AUTOSAR XML (schema 00051)
package /DBC_SysDesc_Can_Network/Pkg_Cluster
  can cluster Can_Network: protocol-name=CAN
    can physical channel Can_Network_Channel: comm-connectors=Connector_Network_Can_Node0_TPMS
      frame FrameCan_BCM_01_LOGICAL_CLAMP: id 0x102, to Ecu_TPMS, frame-length=16, can-addressing-mode=STANDARD, can-fd-frame-support=false, can-frame-rx-behavior=CAN-FD  # Logical clamps, crank and starter relais (controlled by BCM) /clamp CES"
        carries pdu IPduISignal_BCM_01_LOGICAL_CLAMP: packing-byte-order=big-endian, start-position=7
        pdu IPduISignal_BCM_01_LOGICAL_CLAMP: length=16, transmission-mode-false-timing=cyclic-timing={time-offset=0.0, time-period=0.1}, transmission-mode-true-timing=cyclic-timing={time-offset=0.0, time-period=0.1}  # Logical clamps, crank and starter relais (controlled by BCM) /clamp CES
          transmission-mode-conditions:
            {data-filter={data-filter-type=NEW-IS-WITHIN, max=18446744073709551615, min=0, offset=0}, i-signal-in-i-pdu=SSecOC_MAC_BCM_01}
            {data-filter={data-filter-type=ALWAYS, max=255, min=0, offset=0}, i-signal-in-i-pdu=SSecOC_Fresh_BCM_01}
            {data-filter={data-filter-type=ALWAYS, max=3, min=0, offset=0}, i-signal-in-i-pdu=STAT_StartStopButton}
            {data-filter={data-filter-type=ALWAYS, max=3, min=0, offset=0}, i-signal-in-i-pdu=BCM_Cl30R_Off_Announcement}
            {data-filter={data-filter-type=ALWAYS, max=3, min=0, offset=0}, i-signal-in-i-pdu=BCM_Cl30s_Off_Announcement}
            {data-filter={data-filter-type=ALWAYS, max=3, min=0, offset=0}, i-signal-in-i-pdu=BCM_STAT_TransportMode}
            {data-filter={data-filter-type=ALWAYS, max=3, min=0, offset=0}, i-signal-in-i-pdu=BCM_KL15_Off_Announcement}
            {data-filter={data-filter-type=ALWAYS, max=15, min=0, offset=0}, i-signal-in-i-pdu=BCM_ST_KL}
            {data-filter={data-filter-type=ALWAYS, max=7, min=0, offset=0}, i-signal-in-i-pdu=BCM_STAT_Terminal}
            {data-filter={data-filter-type=ALWAYS, max=3, min=0, offset=0}, i-signal-in-i-pdu=BCM_STAT_CL30R_L}
            {data-filter={data-filter-type=ALWAYS, max=3, min=0, offset=0}, i-signal-in-i-pdu=BCM_STAT_CL30s_L}
            {data-filter={data-filter-type=NEW-IS-WITHIN, max=65535, min=0, offset=0}, i-signal-in-i-pdu=CRC_BCM_01}
            {data-filter={data-filter-type=ALWAYS, max=255, min=0, offset=0}, i-signal-in-i-pdu=ALIVE_BCM_01}
            {data-filter={data-filter-type=ALWAYS, max=3, min=0, offset=0}, i-signal-in-i-pdu=BCM_STAT_CL15_L}
          signal SSecOC_MAC_BCM_01: start 39, 64 bit, big-endian, init-value=0, base-type=uint64, compu {raw=phys for phys 0..1.84467440737096E19}, end-to-end-transformation-i-signal-props=data-ids=0, to Ecu_TPMS  # Short SecOC MAC signal byte 0 on CAN"
          signal SSecOC_Fresh_BCM_01: start 31, 8 bit, big-endian, init-value=0, base-type=uint8, compu {raw=phys for phys 0..255}, end-to-end-transformation-i-signal-props=data-ids=0, to Ecu_TPMS  # Short SecOC Fresh signal byte 0 on CAN"
          signal STAT_StartStopButton: start 115, 2 bit, big-endian, init-value=0, base-type=uint8, compu {phys=raw for raw 0..3, 0=NOTPRESSED, 1=PRESSED, 2=RESERVED, 3=SIGNALINVALID}, end-to-end-transformation-i-signal-props=data-ids=0, to Ecu_TPMS
          signal BCM_Cl30R_Off_Announcement: start 125, 2 bit, big-endian, init-value=0, base-type=uint8, compu {phys=raw for raw 0..3, 0=NOTAVAILABLE, 1=NO_CL30R_ANNOUNCEMENT, 2=CL30R_SHUTDOWN_ANNOUNCEMENT, 3=RESERVED}, end-to-end-transformation-i-signal-props=data-ids=0, to Ecu_TPMS
          signal BCM_Cl30s_Off_Announcement: start 127, 2 bit, big-endian, init-value=0, base-type=uint8, compu {phys=raw for raw 0..3, 0=NOTAVAILABLE, 1=NO_CL30S_ANNOUNCEMENT, 2=CL30S_SHUTDOWN_ANNOUNCEMENT, 3=RESERVED}, end-to-end-transformation-i-signal-props=data-ids=0, to Ecu_TPMS
          signal BCM_STAT_TransportMode: start 117, 2 bit, big-endian, init-value=0, base-type=uint8, compu {phys=raw for raw 0..3, 0=NOTACTIVE, 1=ACTIVE, 2=RESERVED, 3=INVALID}, end-to-end-transformation-i-signal-props=data-ids=0, to Ecu_TPMS  # Transport Mode"
          signal BCM_KL15_Off_Announcement: start 119, 2 bit, big-endian, init-value=0, base-type=uint8, compu {phys=raw for raw 0..3, 0=NOTAVAILABLE, 1=NO_ANNOUNCEMENT, 2=KL15_SHUTDOWN_ANNOUNCED, 3=RESERVED}, end-to-end-transformation-i-signal-props=data-ids=0, to Ecu_TPMS  # Before switching off the KL15 (5s), this signal gets active to inform other ECUs that the KL15 will be disabled in 5seconds if there are still no triggers to keep it active"
          signal BCM_ST_KL: start 108, 4 bit, big-endian, init-value=0, base-type=uint8, compu {phys=raw for raw 0..15, 0=INIT, 2=KL30, 15=SIGNALINVALID}, end-to-end-transformation-i-signal-props=data-ids=0, to Ecu_TPMS  # Clamp Status"
          signal BCM_STAT_Terminal: start 111, 3 bit, big-endian, init-value=0, base-type=uint8, compu {phys=raw for raw 0..7, 0=OFF, 1=THREE0S, 2=THREE0S_THREE0RON, 3=THREE0S_THREE0R_15ON, 4=RESERVED, 5=RESERVED, 6=RESERVED, 7=SIGNALINVALID}, end-to-end-transformation-i-signal-props=data-ids=0, to Ecu_TPMS  # Represent the status of physical terminal"
          signal BCM_STAT_CL30R_L: start 99, 2 bit, big-endian, init-value=3, base-type=uint8, compu {phys=raw for raw 0..3, 0=CL_30R_LOFF, 1=CL_30R_LON, 2=FAILURE, 3=SIGNALINVALID}, end-to-end-transformation-i-signal-props=data-ids=0, to Ecu_TPMS  # CL30R clamp status"
          signal BCM_STAT_CL30s_L: start 101, 2 bit, big-endian, init-value=3, base-type=uint8, compu {phys=raw for raw 0..3, 0=CL_30SOFF, 1=CL_30SON, 2=FAILURE, 3=SIGNALINVALID}, end-to-end-transformation-i-signal-props=data-ids=0, to Ecu_TPMS  # CL30s clamp status"
          signal CRC_BCM_01: start 7, 16 bit, big-endian, init-value=0, base-type=uint16, compu {raw=phys for phys 0..65535}, end-to-end-transformation-i-signal-props=data-ids=0, to Ecu_TPMS  # DataID=0x0007. Checksum calculation accordig CAN Specification. Cyclic Redundancy Check"
          signal ALIVE_BCM_01: start 23, 8 bit, big-endian, init-value=0, base-type=uint8, compu {raw=phys for phys 0..255}, end-to-end-transformation-i-signal-props=data-ids=0, to Ecu_TPMS  # Alive Counter"
          signal BCM_STAT_CL15_L: start 103, 2 bit, big-endian, init-value=3, base-type=uint8, compu {phys=raw for raw 0..3, 0=CL_15_LOFF, 1=CL_15_LON, 2=FAILURE, 3=SIGNALINVALID}, end-to-end-transformation-i-signal-props=data-ids=0, to Ecu_TPMS  # CL15 clamp status"
      frame FrameCan_CGW_01_CON_VEH: id 0x1B1, to Ecu_TPMS, frame-length=16, can-addressing-mode=STANDARD, can-fd-frame-support=false, can-frame-rx-behavior=CAN-FD  # CES clamp"
        carries pdu IPduISignal_CGW_01_CON_VEH: packing-byte-order=big-endian, start-position=7
        pdu IPduISignal_CGW_01_CON_VEH: length=16, transmission-mode-false-timing=cyclic-timing={time-offset=0.0, time-period=0.1}, transmission-mode-true-timing=cyclic-timing={time-offset=0.0, time-period=0.1}  # CES clamp
          transmission-mode-conditions:
            {data-filter={data-filter-type=NEW-IS-WITHIN, max=18446744073709551615, min=0, offset=0}, i-signal-in-i-pdu=SSecOC_MAC_CGW_01}
            {data-filter={data-filter-type=ALWAYS, max=255, min=0, offset=0}, i-signal-in-i-pdu=ALIVE_CGW_01}
            {data-filter={data-filter-type=NEW-IS-WITHIN, max=65535, min=0, offset=0}, i-signal-in-i-pdu=CRC_CGW_01}
            {data-filter={data-filter-type=ALWAYS, max=15, min=0, offset=0}, i-signal-in-i-pdu=VEH_State}
            {data-filter={data-filter-type=ALWAYS, max=255, min=0, offset=0}, i-signal-in-i-pdu=SSecOC_Fresh_CGW_01}
            {data-filter={data-filter-type=ALWAYS, max=3, min=0, offset=0}, i-signal-in-i-pdu=CGW_OBDConnectStatus}
          signal SSecOC_MAC_CGW_01: start 39, 64 bit, big-endian, init-value=0, base-type=uint64, compu {raw=phys for phys 0..1.84467440737096E19}, end-to-end-transformation-i-signal-props=data-ids=0, to Ecu_TPMS  # Short SecOC MAC signal byte 0 on CAN"
          signal ALIVE_CGW_01: start 23, 8 bit, big-endian, init-value=0, base-type=uint8, compu {raw=phys for phys 0..255}, end-to-end-transformation-i-signal-props=data-ids=0, to Ecu_TPMS  # Alive Counter"
          signal CRC_CGW_01: start 7, 16 bit, big-endian, init-value=0, base-type=uint16, compu {raw=phys for phys 0..65535}, end-to-end-transformation-i-signal-props=data-ids=0, to Ecu_TPMS  # DataID=0x0018. Checksum calculation accordig CAN Specification. Cyclic Redundancy Check"
          signal VEH_State: start 103, 4 bit, big-endian, init-value=0, base-type=uint8, compu {phys=raw for raw 0..15, 0=SLEEP, 1=ACCESS, 13=RESERVED, 2=STANDBY, 14=RESERVED, 3=PREPARE, 15=SIGNALINVALID, 4=DRIVE, 5=CHARGING, 6=DIAGNOSTIC, 7=END_DRIVE}, end-to-end-transformation-i-signal-props=data-ids=0, to Ecu_TPMS  # Vehicle Mode"
          signal SSecOC_Fresh_CGW_01: start 31, 8 bit, big-endian, init-value=0, base-type=uint8, compu {raw=phys for phys 0..255}, end-to-end-transformation-i-signal-props=data-ids=0, to Ecu_TPMS  # Short SecOC Fresh signal byte 0 on CAN"
          signal CGW_OBDConnectStatus: start 99, 2 bit, big-endian, init-value=0, base-type=uint8, compu {phys=raw for raw 0..3, 0=INITIAL, 1=CONNECTED, 2=NOTCONNECTED, 3=INVALID}, end-to-end-transformation-i-signal-props=data-ids=0, to Ecu_TPMS  # CGW send the OBD port connection status to All CANFD buses"
      frame FrameCan_Diag_ReqPhys_TPMS: id 0x18DA19F1, to Ecu_TPMS, frame-length=64, can-addressing-mode=EXTENDED, can-fd-frame-support=false, can-frame-rx-behavior=CAN-FD
        carries pdu IPduDcm_Diag_ReqPhys_TPMS: packing-byte-order=big-endian, start-position=7
        dcm i pdu IPduDcm_Diag_ReqPhys_TPMS: length=64, diag-pdu-type=DIAG-REQUEST
      frame FrameCan_ESC_01_VeloSpeed: id 0x144, to Ecu_TPMS, frame-length=48, can-addressing-mode=STANDARD, can-fd-frame-support=false, can-frame-rx-behavior=CAN-FD  # ESC_Velospeed - Vehicle speed, wheele speed, milage"
        carries pdu IPduISignal_ESC_01_VeloSpeed: packing-byte-order=big-endian, start-position=7
        pdu IPduISignal_ESC_01_VeloSpeed: length=48, transmission-mode-false-timing=cyclic-timing={time-offset=0.0, time-period=0.01}, transmission-mode-true-timing=cyclic-timing={time-offset=0.0, time-period=0.01}  # ESC_Velospeed - Vehicle speed, wheele speed, milage
          transmission-mode-conditions:
            {data-filter={data-filter-type=ALWAYS, max=15, min=0, offset=0}, i-signal-in-i-pdu=ESC_VehSpdLat_Q}
            {data-filter={data-filter-type=NEW-IS-WITHIN, max=22400, min=0, offset=0}, i-signal-in-i-pdu=ESC_VehSpdLat}
            {data-filter={data-filter-type=NEW-IS-WITHIN, max=18446744073709551615, min=0, offset=0}, i-signal-in-i-pdu=SSecOC_MAC_ESC_01}
            {data-filter={data-filter-type=ALWAYS, max=255, min=0, offset=0}, i-signal-in-i-pdu=SSecOC_Fresh_ESC_01}
            {data-filter={data-filter-type=ALWAYS, max=3, min=0, offset=0}, i-signal-in-i-pdu=ESC_WhlTck_RR_Q}
            {data-filter={data-filter-type=ALWAYS, max=3, min=0, offset=0}, i-signal-in-i-pdu=ESC_WhlTck_RL_Q}
            {data-filter={data-filter-type=ALWAYS, max=3, min=0, offset=0}, i-signal-in-i-pdu=ESC_WhlTck_FR_Q}
            {data-filter={data-filter-type=ALWAYS, max=254, min=0, offset=0}, i-signal-in-i-pdu=ESC_WhlTck_RR}
            {data-filter={data-filter-type=ALWAYS, max=254, min=0, offset=0}, i-signal-in-i-pdu=ESC_WhlTck_RL}
            {data-filter={data-filter-type=ALWAYS, max=254, min=0, offset=0}, i-signal-in-i-pdu=ESC_WhlTck_FR}
            {data-filter={data-filter-type=ALWAYS, max=3, min=0, offset=0}, i-signal-in-i-pdu=ESC_WhlTck_FL_Q}
            {data-filter={data-filter-type=ALWAYS, max=254, min=0, offset=0}, i-signal-in-i-pdu=ESC_WhlTck_FL}
            {data-filter={data-filter-type=ALWAYS, max=3, min=0, offset=0}, i-signal-in-i-pdu=ESC_WhlSpd_RR_Q}
            {data-filter={data-filter-type=NEW-IS-WITHIN, max=25600, min=-25600, offset=0}, i-signal-in-i-pdu=ESC_WhlSpd_RR}
            {data-filter={data-filter-type=ALWAYS, max=3, min=0, offset=0}, i-signal-in-i-pdu=ESC_WhlSpd_RL_Q}
            {data-filter={data-filter-type=NEW-IS-WITHIN, max=25600, min=-25600, offset=0}, i-signal-in-i-pdu=ESC_WhlSpd_RL}
            {data-filter={data-filter-type=ALWAYS, max=3, min=0, offset=0}, i-signal-in-i-pdu=ESC_WhlSpd_FR_Q}
            {data-filter={data-filter-type=NEW-IS-WITHIN, max=25600, min=-25600, offset=0}, i-signal-in-i-pdu=ESC_WhlSpd_FR}
            {data-filter={data-filter-type=ALWAYS, max=3, min=0, offset=0}, i-signal-in-i-pdu=ESC_WhlSpd_FL_Q}
            {data-filter={data-filter-type=NEW-IS-WITHIN, max=25600, min=-25600, offset=0}, i-signal-in-i-pdu=ESC_WhlSpd_FL}
            {data-filter={data-filter-type=ALWAYS, max=3, min=0, offset=0}, i-signal-in-i-pdu=ESC_VehDrvCond_Q}
            {data-filter={data-filter-type=ALWAYS, max=3, min=0, offset=0}, i-signal-in-i-pdu=ESC_DrivDist_Q}
            {data-filter={data-filter-type=ALWAYS, max=255, min=0, offset=0}, i-signal-in-i-pdu=ALIVE_ESC_01}
            {data-filter={data-filter-type=NEW-IS-WITHIN, max=65535, min=0, offset=0}, i-signal-in-i-pdu=CRC_ESC_01}
            {data-filter={data-filter-type=NEW-IS-WITHIN, max=65535, min=0, offset=0}, i-signal-in-i-pdu=ESC_DrivDist}
            {data-filter={data-filter-type=ALWAYS, max=3, min=0, offset=0}, i-signal-in-i-pdu=ESC_VehDrvCond}
            {data-filter={data-filter-type=ALWAYS, max=3, min=0, offset=0}, i-signal-in-i-pdu=ESC_VehSpd_Q}
            {data-filter={data-filter-type=NEW-IS-WITHIN, max=22400, min=0, offset=0}, i-signal-in-i-pdu=ESC_VehSpd}
          signal ESC_VehSpdLat_Q: start 311, 4 bit, big-endian, init-value=0, base-type=uint8, compu {phys=raw for raw 0..15, 11=QUALITYLIMITEDSTATUSTEMPORARY, 12=REPLACEMENTVALUESTATUSTEMP, 13=REPLACEMENTVALUE, 14=SIGNALINVALIDSTATUSTEMPORARY, 15=SIGNALINVALID, 0=INITIALIZING, 1..4=RESERVED, 5=VALID, 6..9=RESERVED, 10=VALUEISVALIDSTATUSTEMPORARY}, end-to-end-transformation-i-signal-props=data-ids=0, to Ecu_TPMS  # Qualifier Lateral Vehicle Speed"
          signal ESC_VehSpdLat: start 295, 16 bit, big-endian, init-value=0, base-type=uint16, compu {raw=phys*64 for phys 0..350; unit km_h}, end-to-end-transformation-i-signal-props=data-ids=0, to Ecu_TPMS  # Lateral Vehicle Speed (qualifier Lateral Vehicle Speed)"
          signal SSecOC_MAC_ESC_01: start 39, 64 bit, big-endian, init-value=0, base-type=uint64, compu {raw=phys for phys 0..1.84467440737096E19}, end-to-end-transformation-i-signal-props=data-ids=0, to Ecu_TPMS  # Short SecOC MAC signal byte 0 on CAN"
          signal SSecOC_Fresh_ESC_01: start 31, 8 bit, big-endian, init-value=0, base-type=uint8, compu {raw=phys for phys 0..255}, end-to-end-transformation-i-signal-props=data-ids=0, to Ecu_TPMS  # Short SecOC Fresh signal byte 0 on CAN"
          signal ESC_WhlTck_RR_Q: start 283, 2 bit, big-endian, init-value=0, base-type=uint8, compu {phys=raw for raw 0..3, 0=INITIALIZING, 1=VALID, 2=RESERVED, 3=INVALID}, end-to-end-transformation-i-signal-props=data-ids=0, to Ecu_TPMS  # Qualifier Wheel Tick RR"
          signal ESC_WhlTck_RL_Q: start 287, 2 bit, big-endian, init-value=0, base-type=uint8, compu {phys=raw for raw 0..3, 0=INITIALIZING, 1=VALID, 2=RESERVED, 3=INVALID}, end-to-end-transformation-i-signal-props=data-ids=0, to Ecu_TPMS  # Qualifier Wheel Tick RL"
          signal ESC_WhlTck_FR_Q: start 275, 2 bit, big-endian, init-value=0, base-type=uint8, compu {phys=raw for raw 0..3, 0=INITIALIZING, 1=VALID, 2=RESERVED, 3=INVALID}, end-to-end-transformation-i-signal-props=data-ids=0, to Ecu_TPMS  # Qualifier Wheel Tick FR"
          signal ESC_WhlTck_RR: start 271, 8 bit, big-endian, init-value=0, base-type=uint8, compu {raw=phys for phys 0..254; unit Tick}, end-to-end-transformation-i-signal-props=data-ids=0, to Ecu_TPMS  # Wheel tick (pulse counter) of rear right wheel. A tick is counted every rising and falling edge of teeth. The ticks are accumulated. No ticks must be lost or added."
          signal ESC_WhlTck_RL: start 263, 8 bit, big-endian, init-value=0, base-type=uint8, compu {raw=phys for phys 0..254; unit Tick}, end-to-end-transformation-i-signal-props=data-ids=0, to Ecu_TPMS  # Wheel tick (pulse counter) of rear left wheel. A tick is counted every rising and falling edge of teeth. The ticks are accumulated. No ticks must be lost or added."
          signal ESC_WhlTck_FR: start 255, 8 bit, big-endian, init-value=0, base-type=uint8, compu {raw=phys for phys 0..254; unit Tick}, end-to-end-transformation-i-signal-props=data-ids=0, to Ecu_TPMS  # Wheel tick (pulse counter) of front right wheel. A tick is counted every rising and falling edge of teeth. The ticks are accumulated. No ticks must be lost or added."
          signal ESC_WhlTck_FL_Q: start 279, 2 bit, big-endian, init-value=0, base-type=uint8, compu {phys=raw for raw 0..3, 0=INITIALIZING, 1=VALID, 2=RESERVED, 3=INVALID}, end-to-end-transformation-i-signal-props=data-ids=0, to Ecu_TPMS  # Qualifier Wheel Tick FL"
          signal ESC_WhlTck_FL: start 247, 8 bit, big-endian, init-value=0, base-type=uint8, compu {raw=phys for phys 0..254; unit Tick}, end-to-end-transformation-i-signal-props=data-ids=0, to Ecu_TPMS  # Wheel tick (pulse counter) of front left wheel. A tick is counted every rising and falling edge of teeth. The ticks are accumulated. No ticks must be lost or added."
          signal ESC_WhlSpd_RR_Q: start 223, 2 bit, big-endian, init-value=0, base-type=uint8, compu {phys=raw for raw 0..3, 0=INITIALIZING, 1=VALID, 2=REPLACEMENTVALUE, 3=SIGNALINVALID}, end-to-end-transformation-i-signal-props=data-ids=0, to Ecu_TPMS  # Qualifier wheel speed rear right"
          signal ESC_WhlSpd_RR: start 207, 16 bit, big-endian, init-value=0, base-type=sint16, compu {raw=phys*64 for phys -400..400; unit rad_s}, end-to-end-transformation-i-signal-props=data-ids=0, to Ecu_TPMS  # Measured speed of the rear right single wheel."
          signal ESC_WhlSpd_RL_Q: start 199, 2 bit, big-endian, init-value=0, base-type=uint8, compu {phys=raw for raw 0..3, 0=INITIALIZING, 1=VALID, 2=REPLACEMENTVALUE, 3=SIGNALINVALID}, end-to-end-transformation-i-signal-props=data-ids=0, to Ecu_TPMS  # Qualifier wheel speed rear left"
          signal ESC_WhlSpd_RL: start 183, 16 bit, big-endian, init-value=0, base-type=sint16, compu {raw=phys*64 for phys -400..400; unit rad_s}, end-to-end-transformation-i-signal-props=data-ids=0, to Ecu_TPMS  # Measured speed of the rear left single wheel."
          signal ESC_WhlSpd_FR_Q: start 175, 2 bit, big-endian, init-value=0, base-type=uint8, compu {phys=raw for raw 0..3, 0=INITIALIZING, 1=VALID, 2=REPLACEMENTVALUE, 3=SIGNALINVALID}, end-to-end-transformation-i-signal-props=data-ids=0, to Ecu_TPMS  # Qualifier for wheel speed front right"
          signal ESC_WhlSpd_FR: start 159, 16 bit, big-endian, init-value=0, base-type=sint16, compu {raw=phys*64 for phys -400..400; unit rad_s}, end-to-end-transformation-i-signal-props=data-ids=0, to Ecu_TPMS  # Measured speed of the front right single wheel."
          signal ESC_WhlSpd_FL_Q: start 151, 2 bit, big-endian, init-value=0, base-type=uint8, compu {phys=raw for raw 0..3, 0=INITIALIZING, 1=VALID, 2=REPLACEMENTVALUE, 3=SIGNALINVALID}, end-to-end-transformation-i-signal-props=data-ids=0, to Ecu_TPMS  # Qualifier for wheel speed front left"
          signal ESC_WhlSpd_FL: start 135, 16 bit, big-endian, init-value=0, base-type=sint16, compu {raw=phys*64 for phys -400..400; unit rad_s}, end-to-end-transformation-i-signal-props=data-ids=0, to Ecu_TPMS  # Measured speed of the front left single wheel."
          signal ESC_VehDrvCond_Q: start 127, 2 bit, big-endian, init-value=0, base-type=uint8, compu {phys=raw for raw 0..3, 0=INITIALIZING, 1=VALID, 2=RESERVED, 3=SIGNALINVALID}, end-to-end-transformation-i-signal-props=data-ids=0, to Ecu_TPMS  # Qualifier Driving Condition Detected: Stationary, Moving Forwards, Moving Backwards"
          signal ESC_DrivDist_Q: start 219, 2 bit, big-endian, init-value=0, base-type=uint8, compu {phys=raw for raw 0..3, 0=INITIALIZING, 1=VALID, 2=RESERVED, 3=INVALID}, end-to-end-transformation-i-signal-props=data-ids=0, to Ecu_TPMS  # Qualifier ESC_Mileage: 1 cm / Digit; invalid value FFFFh, input for Mileage calc, in cm, reset each clamp change"
          signal ALIVE_ESC_01: start 23, 8 bit, big-endian, init-value=0, base-type=uint8, compu {raw=phys for phys 0..255}, end-to-end-transformation-i-signal-props=data-ids=0, to Ecu_TPMS  # Alive Counter"
          signal CRC_ESC_01: start 7, 16 bit, big-endian, init-value=0, base-type=uint16, compu {raw=phys for phys 0..65535}, end-to-end-transformation-i-signal-props=data-ids=0, to Ecu_TPMS  # DataID=0x0025. Checksum calculation accordig CAN Specification. Cyclic Redundancy Check"
          signal ESC_DrivDist: start 231, 16 bit, big-endian, init-value=0, base-type=uint16, compu {raw=phys for phys 0..65535; unit cm}, end-to-end-transformation-i-signal-props=data-ids=0, to Ecu_TPMS  # ESC_Mileage: 1 cm / Digit; invalid value FFFFh, input for Mileage calc, in cm, reset each clamp change"
          signal ESC_VehDrvCond: start 115, 2 bit, big-endian, init-value=0, base-type=uint8, compu {phys=raw for raw 0..3, 0=STANDSTILL, 1=FORWARD, 2=BACKWARD, 3=INVALID}, end-to-end-transformation-i-signal-props=data-ids=0, to Ecu_TPMS  # Driving Condition Detected: Driving condition Values 4,5,6 describe if the axle are on the chassis dynamometer roller dynamometer test bench; Value 3 described when the recognition of the moving direction isn't recognised."
          signal ESC_VehSpd_Q: start 119, 2 bit, big-endian, init-value=0, base-type=uint8, compu {phys=raw for raw 0..3, 0=INITIALIZING, 1=VALID, 2=QUALITYLIMITEDSTATUSTEMP, 3=SIGNALINVALID}, end-to-end-transformation-i-signal-props=data-ids=0, to Ecu_TPMS  # Qualifier Vehicle Speed"
          signal ESC_VehSpd: start 103, 16 bit, big-endian, init-value=0, base-type=uint16, compu {raw=phys*64 for phys 0..350; unit km_h}, end-to-end-transformation-i-signal-props=data-ids=0, to Ecu_TPMS  # Vehicle Speed"
      frame FrameCan_ESC_05_OTA: id 0x312, to Ecu_TPMS, frame-length=16, can-addressing-mode=STANDARD, can-fd-frame-support=false, can-frame-rx-behavior=CAN-FD
        carries pdu IPduISignal_ESC_05_OTA: packing-byte-order=big-endian, start-position=7
        pdu IPduISignal_ESC_05_OTA: length=16, transmission-mode-false-timing=cyclic-timing={time-offset=0.0, time-period=0.5}, transmission-mode-true-timing=cyclic-timing={time-offset=0.0, time-period=0.5}
          transmission-mode-conditions:
            {data-filter={data-filter-type=ALWAYS, max=255, min=0, offset=0}, i-signal-in-i-pdu=ALIVE_ESC_05}
            {data-filter={data-filter-type=NEW-IS-WITHIN, max=65535, min=0, offset=0}, i-signal-in-i-pdu=CRC_ESC_05}
            {data-filter={data-filter-type=ALWAYS, max=3, min=0, offset=0}, i-signal-in-i-pdu=ESC_OTA_inhib_FB}
          signal ALIVE_ESC_05: start 23, 8 bit, big-endian, init-value=0, base-type=uint8, compu {raw=phys for phys 0..255}, end-to-end-transformation-i-signal-props=data-ids=0, to Ecu_TPMS  # Alive Counter"
          signal CRC_ESC_05: start 7, 16 bit, big-endian, init-value=0, base-type=uint16, compu {raw=phys for phys 0..65535}, end-to-end-transformation-i-signal-props=data-ids=0, to Ecu_TPMS  # DataID=0x0029. Checksum calculation accordig CAN Specification. Cyclic Redundancy Check"
          signal ESC_OTA_inhib_FB: start 103, 2 bit, big-endian, init-value=0, base-type=uint8, compu {phys=raw for raw 0..3, 0=INITIAL, 1=INHIBITED, 2=NOTINHIBITED, 3=INVALID}, end-to-end-transformation-i-signal-props=data-ids=0, to Ecu_TPMS  # ESC execute the inhibition and send the Feedback to all CANFD ECUs"
      frame FrameCan_HU_01_OTA: id 0x313, to Ecu_TPMS, frame-length=16, can-addressing-mode=STANDARD, can-fd-frame-support=false, can-frame-rx-behavior=CAN-FD
        carries pdu IPduISignal_HU_01_OTA: packing-byte-order=big-endian, start-position=7
        pdu IPduISignal_HU_01_OTA: length=16, transmission-mode-false-timing=cyclic-timing={time-offset=0.0, time-period=0.5}, transmission-mode-true-timing=cyclic-timing={time-offset=0.0, time-period=0.5}
          transmission-mode-conditions:
            {data-filter={data-filter-type=ALWAYS, max=255, min=0, offset=0}, i-signal-in-i-pdu=ALIVE_HU_01}
            {data-filter={data-filter-type=NEW-IS-WITHIN, max=65535, min=0, offset=0}, i-signal-in-i-pdu=CRC_HU_01}
            {data-filter={data-filter-type=ALWAYS, max=7, min=0, offset=0}, i-signal-in-i-pdu=HU_OTA_UpdateConfirm}
          signal ALIVE_HU_01: start 23, 8 bit, big-endian, init-value=0, base-type=uint8, compu {raw=phys for phys 0..255}, end-to-end-transformation-i-signal-props=data-ids=0, to Ecu_TPMS  # Alive Counter"
          signal CRC_HU_01: start 7, 16 bit, big-endian, init-value=0, base-type=uint16, compu {raw=phys for phys 0..65535}, end-to-end-transformation-i-signal-props=data-ids=0, to Ecu_TPMS  # DataID=0x002D. Checksum calculation accordig CAN Specification. Cyclic Redundancy Check"
          signal HU_OTA_UpdateConfirm: start 103, 3 bit, big-endian, init-value=0, base-type=uint8, compu {phys=raw for raw 0..7, 0=INITIAL, 1=OTAUPDATECONFIRMED, 2=OTAFINISHED, 3..6=RESERVED, 7=INVALID}, end-to-end-transformation-i-signal-props=data-ids=0, to Ecu_TPMS  # HU send the input confirmation of updating from user to all CANFD ECUs"
      frame FrameCan_HU_03_SET_FUNC: id 0x3FA, to Ecu_TPMS, frame-length=16, can-addressing-mode=STANDARD, can-fd-frame-support=false, can-frame-rx-behavior=CAN-FD  # Settings for customer functions, mode functions"
        carries pdu IPduISignal_HU_03_SET_FUNC: packing-byte-order=big-endian, start-position=7
        pdu IPduISignal_HU_03_SET_FUNC: length=16  # Settings for customer functions, mode functions
          transmission-mode-conditions:
            {data-filter={data-filter-type=ALWAYS, max=0, min=0, offset=0}, i-signal-in-i-pdu=SET_TowMode}
            {data-filter={data-filter-type=ALWAYS, max=255, min=0, offset=0}, i-signal-in-i-pdu=ALIVE_HU_03}
            {data-filter={data-filter-type=NEW-IS-WITHIN, max=65535, min=0, offset=0}, i-signal-in-i-pdu=CRC_HU_03}
            {data-filter={data-filter-type=ALWAYS, max=3, min=0, offset=0}, i-signal-in-i-pdu=SteeringHeatingRequest}
            {data-filter={data-filter-type=ALWAYS, max=3, min=0, offset=0}, i-signal-in-i-pdu=SET_InteriorMotionSensing}
            {data-filter={data-filter-type=ALWAYS, max=3, min=0, offset=0}, i-signal-in-i-pdu=SET_RCP_Button}
            {data-filter={data-filter-type=ALWAYS, max=100, min=0, offset=0}, i-signal-in-i-pdu=DimmingVehicleBrightness}
            {data-filter={data-filter-type=ALWAYS, max=3, min=0, offset=0}, i-signal-in-i-pdu=SET_DayTimeRunningLight}
            {data-filter={data-filter-type=ALWAYS, max=7, min=0, offset=0}, i-signal-in-i-pdu=SET_LeavingHomeSetting}
            {data-filter={data-filter-type=ALWAYS, max=7, min=0, offset=0}, i-signal-in-i-pdu=SET_ComingHomeSetting}
            {data-filter={data-filter-type=ALWAYS, max=3, min=0, offset=0}, i-signal-in-i-pdu=SET_ToDefaultFactorySetting}
            {data-filter={data-filter-type=ALWAYS, max=3, min=0, offset=0}, i-signal-in-i-pdu=SET_RemoteLockFeedback}
          signal SET_TowMode: start 127, 2 bit, big-endian, init-value=0, base-type=uint8, compu {phys=raw for raw 0, 0=OFF, 1=ON, 2=NOCHANGE, 3=SIGNALINVALID}, end-to-end-transformation-i-signal-props=data-ids=0, to Ecu_TPMS
          signal ALIVE_HU_03: start 23, 8 bit, big-endian, init-value=0, base-type=uint8, compu {raw=phys for phys 0..255}, end-to-end-transformation-i-signal-props=data-ids=0, to Ecu_TPMS  # Alive Counter"
          signal CRC_HU_03: start 7, 16 bit, big-endian, init-value=0, base-type=uint16, compu {raw=phys for phys 0..65535}, end-to-end-transformation-i-signal-props=data-ids=0, to Ecu_TPMS  # DataID=0x002F. Checksum calculation accordig CAN Specification. Cyclic Redundancy Check"
          signal SteeringHeatingRequest: start 117, 2 bit, big-endian, init-value=0, base-type=uint8, compu {raw=phys for phys 0..3}, end-to-end-transformation-i-signal-props=data-ids=0, to Ecu_TPMS
          signal SET_InteriorMotionSensing: start 119, 2 bit, big-endian, init-value=0, base-type=uint8, compu {phys=raw for raw 0..3, 0=OFF, 1=ON, 2=NOCHANGE, 3=SIGNALINVALID}, end-to-end-transformation-i-signal-props=data-ids=0, to Ecu_TPMS
          signal SET_RCP_Button: start 113, 2 bit, big-endian, init-value=0, base-type=uint8, compu {phys=raw for raw 0..3, 0=NOTPRESSED, 1=PRESSED, 2=RESERVED, 3=SIGNALINVALID}, end-to-end-transformation-i-signal-props=data-ids=0, to Ecu_TPMS  # RCP softbutton status inside ICH, Display menue button information"
          signal DimmingVehicleBrightness: start 111, 8 bit, big-endian, init-value=0, base-type=uint8, compu {raw=phys for phys 0..100; unit pct}, end-to-end-transformation-i-signal-props=data-ids=0, to Ecu_TPMS  # 255 invalid value. Valid range 0 - 100% Values between 101 and 254 are reserved. Used for PWM control of clamp 58,"
          signal SET_DayTimeRunningLight: start 103, 2 bit, big-endian, init-value=0, base-type=uint8, compu {phys=raw for raw 0..3, 0=OFF, 1=ON, 2=RESERVED, 3=SIGNALINVALID}, end-to-end-transformation-i-signal-props=data-ids=0, to Ecu_TPMS  # Activation of the day time running light"
          signal SET_LeavingHomeSetting: start 98, 3 bit, big-endian, init-value=0, base-type=uint8, compu {phys=raw for raw 0..7, 0=OFF, 1=TWO0, 2=FOUR0, 3=SIX0, 4=EIGHT0, 5=RESERVED, 6=NOCHANGE, 7=SIGNALINVALID; unit Bit}, end-to-end-transformation-i-signal-props=data-ids=0, to Ecu_TPMS  # Setting for follow me home light function Invalid value = 3"
          signal SET_ComingHomeSetting: start 101, 3 bit, big-endian, init-value=0, base-type=uint8, compu {phys=raw for raw 0..7, 0=OFF, 1=TWO0, 2=FOUR0, 3=SIX0, 4=EIGHT0, 5=RESERVED, 6=NOCHANGE, 7=SIGNALINVALID; unit Bit}, end-to-end-transformation-i-signal-props=data-ids=0, to Ecu_TPMS  # Setting for Leaving home light"
          signal SET_ToDefaultFactorySetting: start 115, 2 bit, big-endian, init-value=0, base-type=uint8, compu {phys=raw for raw 0..3, 0=OFF, 1=ON, 2=RESERVED, 3=SIGNALINVALID_NOCHANGE}, end-to-end-transformation-i-signal-props=data-ids=0, to Ecu_TPMS  # Settings to default values for the ECU's,"
          signal SET_RemoteLockFeedback: start 125, 2 bit, big-endian, init-value=0, base-type=uint8, compu {phys=raw for raw 0..3, 0=NOFEEDBACK, 1=TURNINDICATOR, 2=TURNINDICATOR_TOOT, 3=SIGNALINVALID}, end-to-end-transformation-i-signal-props=data-ids=0, to Ecu_TPMS  # Remote Lock feedback: customer can choose light feedback when lock the door with remote key"
      frame FrameCan_NM_EPS: id 0x510, to Ecu_TPMS, frame-length=8, can-addressing-mode=STANDARD  # Networkmanagement message"
        carries pdu IPduISignal_NM_EPS: packing-byte-order=big-endian, start-position=7
        pdu IPduISignal_NM_EPS: length=8  # Networkmanagement message
          transmission-mode-conditions:
            {data-filter={data-filter-type=ALWAYS, max=1, min=0, offset=0}, i-signal-in-i-pdu=usrData1_EPS_Bit7_ECUSPEC_AWAKE}
            {data-filter={data-filter-type=ALWAYS, max=1, min=0, offset=0}, i-signal-in-i-pdu=usrData1_EPS_Bit6_DIAGN_AWAKE}
            {data-filter={data-filter-type=ALWAYS, max=1, min=0, offset=0}, i-signal-in-i-pdu=usrData1_EPS_Bit5_IGNITION_AWAKE}
            {data-filter={data-filter-type=ALWAYS, max=1, min=0, offset=0}, i-signal-in-i-pdu=usrData1_EPS_Bit4_NETWORK_AWAKE}
            {data-filter={data-filter-type=ALWAYS, max=1, min=0, offset=0}, i-signal-in-i-pdu=usrData1_EPS_Bit3_ECUSPEC_WAKEUP}
            {data-filter={data-filter-type=ALWAYS, max=1, min=0, offset=0}, i-signal-in-i-pdu=usrData1_EPS_Bit2_NETWORK_WAKEUP}
            {data-filter={data-filter-type=ALWAYS, max=1, min=0, offset=0}, i-signal-in-i-pdu=usrData1_EPS_Bit1_RESET_WAKEUP}
            {data-filter={data-filter-type=ALWAYS, max=1, min=0, offset=0}, i-signal-in-i-pdu=CtrlBitVector_EPS_Bit7_Res}
            {data-filter={data-filter-type=ALWAYS, max=1, min=0, offset=0}, i-signal-in-i-pdu=CtrlBitVector_EPS_Bit6_PNI}
            {data-filter={data-filter-type=ALWAYS, max=1, min=0, offset=0}, i-signal-in-i-pdu=CtrlBitVector_EPS_Bit5_Res}
            {data-filter={data-filter-type=ALWAYS, max=1, min=0, offset=0}, i-signal-in-i-pdu=CtrlBitVector_EPS_Bit4_ActWake}
            {data-filter={data-filter-type=ALWAYS, max=1, min=0, offset=0}, i-signal-in-i-pdu=CtrlBitVector_EPS_Bit3_NMCoord}
            {data-filter={data-filter-type=ALWAYS, max=1, min=0, offset=0}, i-signal-in-i-pdu=CtrlBitVector_EPS_Bit2_Res}
            {data-filter={data-filter-type=ALWAYS, max=1, min=0, offset=0}, i-signal-in-i-pdu=CtrlBitVector_EPS_Bit1_Res}
            {data-filter={data-filter-type=ALWAYS, max=1, min=0, offset=0}, i-signal-in-i-pdu=usrData1_EPS_Bit0_IGN_WAKEUP}
            {data-filter={data-filter-type=ALWAYS, max=255, min=0, offset=0}, i-signal-in-i-pdu=usrData0_EPS}
            {data-filter={data-filter-type=ALWAYS, max=127, min=0, offset=0}, i-signal-in-i-pdu=srcNodeID_EPS}
            {data-filter={data-filter-type=ALWAYS, max=1, min=0, offset=0}, i-signal-in-i-pdu=CtrlBitVector_EPS_Bit0_RMR}
            {data-filter={data-filter-type=ALWAYS, max=255, min=0, offset=0}, i-signal-in-i-pdu=usrData2_EPS}
            {data-filter={data-filter-type=ALWAYS, max=255, min=0, offset=0}, i-signal-in-i-pdu=usrData4_EPS_PN_Info1}
            {data-filter={data-filter-type=ALWAYS, max=255, min=0, offset=0}, i-signal-in-i-pdu=usrData5_EPS_PN_Info2}
            {data-filter={data-filter-type=ALWAYS, max=255, min=0, offset=0}, i-signal-in-i-pdu=usrData3_EPS}
          signal usrData1_EPS_Bit7_ECUSPEC_AWAKE: start 31, 1 bit, big-endian, init-value=0, base-type=uint8, compu {phys=raw for raw 0..1, 0=INACTIVE, 1=ACTIVE}, end-to-end-transformation-i-signal-props=data-ids=0, to Ecu_TPMS
          signal usrData1_EPS_Bit6_DIAGN_AWAKE: start 30, 1 bit, big-endian, init-value=0, base-type=uint8, compu {phys=raw for raw 0..1, 0=INACTIVE, 1=ACTIVE}, end-to-end-transformation-i-signal-props=data-ids=0, to Ecu_TPMS
          signal usrData1_EPS_Bit5_IGNITION_AWAKE: start 29, 1 bit, big-endian, init-value=0, base-type=uint8, compu {phys=raw for raw 0..1, 0=INACTIVE, 1=ACTIVE}, end-to-end-transformation-i-signal-props=data-ids=0, to Ecu_TPMS
          signal usrData1_EPS_Bit4_NETWORK_AWAKE: start 28, 1 bit, big-endian, init-value=0, base-type=uint8, compu {phys=raw for raw 0..1, 0=INACTIVE, 1=ACTIVE}, end-to-end-transformation-i-signal-props=data-ids=0, to Ecu_TPMS
          signal usrData1_EPS_Bit3_ECUSPEC_WAKEUP: start 27, 1 bit, big-endian, init-value=0, base-type=uint8, compu {phys=raw for raw 0..1, 0=INACTIVE, 1=ACTIVE}, end-to-end-transformation-i-signal-props=data-ids=0, to Ecu_TPMS
          signal usrData1_EPS_Bit2_NETWORK_WAKEUP: start 26, 1 bit, big-endian, init-value=0, base-type=uint8, compu {phys=raw for raw 0..1, 0=INACTIVE, 1=ACTIVE}, end-to-end-transformation-i-signal-props=data-ids=0, to Ecu_TPMS
          signal usrData1_EPS_Bit1_RESET_WAKEUP: start 25, 1 bit, big-endian, init-value=0, base-type=uint8, compu {phys=raw for raw 0..1, 0=INACTIVE, 1=ACTIVE}, end-to-end-transformation-i-signal-props=data-ids=0, to Ecu_TPMS
          signal CtrlBitVector_EPS_Bit7_Res: start 15, 1 bit, big-endian, init-value=0, base-type=uint8, compu {raw=phys for phys 0..1}, end-to-end-transformation-i-signal-props=data-ids=0, to Ecu_TPMS
          signal CtrlBitVector_EPS_Bit6_PNI: start 14, 1 bit, big-endian, init-value=0, base-type=uint8, compu {raw=phys for phys 0..1}, end-to-end-transformation-i-signal-props=data-ids=0, to Ecu_TPMS
          signal CtrlBitVector_EPS_Bit5_Res: start 13, 1 bit, big-endian, init-value=0, base-type=uint8, compu {raw=phys for phys 0..1}, end-to-end-transformation-i-signal-props=data-ids=0, to Ecu_TPMS
          signal CtrlBitVector_EPS_Bit4_ActWake: start 12, 1 bit, big-endian, init-value=0, base-type=uint8, compu {raw=phys for phys 0..1}, end-to-end-transformation-i-signal-props=data-ids=0, to Ecu_TPMS
          signal CtrlBitVector_EPS_Bit3_NMCoord: start 11, 1 bit, big-endian, init-value=0, base-type=uint8, compu {phys=raw for raw 0..1, 0=STARTOFSYNCHRONIZEDSHUTDOWNISNOTREQUESTEDBYMAINCOORDINATOR, 1=STARTOFSYNCHRONIZEDSHUTDOWNISREQUESTEDBYMAINCOORDINATOR}, end-to-end-transformation-i-signal-props=data-ids=0, to Ecu_TPMS
          signal CtrlBitVector_EPS_Bit2_Res: start 10, 1 bit, big-endian, init-value=0, base-type=uint8, compu {raw=phys for phys 0..1}, end-to-end-transformation-i-signal-props=data-ids=0, to Ecu_TPMS
          signal CtrlBitVector_EPS_Bit1_Res: start 9, 1 bit, big-endian, init-value=0, base-type=uint8, compu {raw=phys for phys 0..1}, end-to-end-transformation-i-signal-props=data-ids=0, to Ecu_TPMS
          signal usrData1_EPS_Bit0_IGN_WAKEUP: start 24, 1 bit, big-endian, init-value=0, base-type=uint8, compu {phys=raw for raw 0..1, 0=INACTIVE, 1=ACTIVE}, end-to-end-transformation-i-signal-props=data-ids=0, to Ecu_TPMS
          signal usrData0_EPS: start 23, 8 bit, big-endian, init-value=0, base-type=uint8, compu {phys=raw for raw 0..255, 0=USERDATAFORCURRENTVEHICLEWITHOUTPARTIALNETWORKING, 1=USERDATAFORCURRENTVEHICLEWITHPARTIALNETWORKING, 255=USERDATANOTUSED}, end-to-end-transformation-i-signal-props=data-ids=0, to Ecu_TPMS
          signal srcNodeID_EPS: start 7, 8 bit, big-endian, init-value=0, base-type=uint8, compu {raw=phys for phys 0..127}, end-to-end-transformation-i-signal-props=data-ids=0, to Ecu_TPMS
          signal CtrlBitVector_EPS_Bit0_RMR: start 8, 1 bit, big-endian, init-value=0, base-type=uint8, compu {raw=phys for phys 0..1}, end-to-end-transformation-i-signal-props=data-ids=0, to Ecu_TPMS
          signal usrData2_EPS: start 39, 8 bit, big-endian, init-value=0, base-type=uint8, compu {raw=phys for phys 0..255}, end-to-end-transformation-i-signal-props=data-ids=0, to Ecu_TPMS
          signal usrData4_EPS_PN_Info1: start 55, 8 bit, big-endian, init-value=0, base-type=uint8, compu {raw=phys for phys 0..255}, end-to-end-transformation-i-signal-props=data-ids=0, to Ecu_TPMS
          signal usrData5_EPS_PN_Info2: start 63, 8 bit, big-endian, init-value=0, base-type=uint8, compu {raw=phys for phys 0..255}, end-to-end-transformation-i-signal-props=data-ids=0, to Ecu_TPMS
          signal usrData3_EPS: start 47, 8 bit, big-endian, init-value=0, base-type=uint8, compu {raw=phys for phys 0..255}, end-to-end-transformation-i-signal-props=data-ids=0, to Ecu_TPMS
      frame FrameCan_NM_ESC: id 0x50F, to Ecu_TPMS, frame-length=8, can-addressing-mode=STANDARD  # Networkmanagement message"
        carries pdu IPduISignal_NM_ESC: packing-byte-order=big-endian, start-position=7
        pdu IPduISignal_NM_ESC: length=8  # Networkmanagement message
          transmission-mode-conditions:
            {data-filter={data-filter-type=ALWAYS, max=1, min=0, offset=0}, i-signal-in-i-pdu=usrData1_ESC_Bit7_ECUSPEC_AWAKE}
            {data-filter={data-filter-type=ALWAYS, max=1, min=0, offset=0}, i-signal-in-i-pdu=usrData1_ESC_Bit6_DIAGN_AWAKE}
            {data-filter={data-filter-type=ALWAYS, max=1, min=0, offset=0}, i-signal-in-i-pdu=usrData1_ESC_Bit5_IGNITION_AWAKE}
            {data-filter={data-filter-type=ALWAYS, max=1, min=0, offset=0}, i-signal-in-i-pdu=usrData1_ESC_Bit4_NETWORK_AWAKE}
            {data-filter={data-filter-type=ALWAYS, max=1, min=0, offset=0}, i-signal-in-i-pdu=usrData1_ESC_Bit3_ECUSPEC_WAKEUP}
            {data-filter={data-filter-type=ALWAYS, max=1, min=0, offset=0}, i-signal-in-i-pdu=usrData1_ESC_Bit2_NETWORK_WAKEUP}
            {data-filter={data-filter-type=ALWAYS, max=1, min=0, offset=0}, i-signal-in-i-pdu=usrData1_ESC_Bit1_RESET_WAKEUP}
            {data-filter={data-filter-type=ALWAYS, max=1, min=0, offset=0}, i-signal-in-i-pdu=CtrlBitVector_ESC_Bit7_Res}
            {data-filter={data-filter-type=ALWAYS, max=1, min=0, offset=0}, i-signal-in-i-pdu=CtrlBitVector_ESC_Bit6_PNI}
            {data-filter={data-filter-type=ALWAYS, max=1, min=0, offset=0}, i-signal-in-i-pdu=CtrlBitVector_ESC_Bit5_Res}
            {data-filter={data-filter-type=ALWAYS, max=1, min=0, offset=0}, i-signal-in-i-pdu=CtrlBitVector_ESC_Bit4_ActWake}
            {data-filter={data-filter-type=ALWAYS, max=1, min=0, offset=0}, i-signal-in-i-pdu=CtrlBitVector_ESC_Bit3_NMCoord}
            {data-filter={data-filter-type=ALWAYS, max=1, min=0, offset=0}, i-signal-in-i-pdu=CtrlBitVector_ESC_Bit2_Res}
            {data-filter={data-filter-type=ALWAYS, max=1, min=0, offset=0}, i-signal-in-i-pdu=CtrlBitVector_ESC_Bit1_Res}
            {data-filter={data-filter-type=ALWAYS, max=1, min=0, offset=0}, i-signal-in-i-pdu=usrData1_ESC_Bit0_IGN_WAKEUP}
            {data-filter={data-filter-type=ALWAYS, max=255, min=0, offset=0}, i-signal-in-i-pdu=usrData0_ESC}
            {data-filter={data-filter-type=ALWAYS, max=127, min=0, offset=0}, i-signal-in-i-pdu=srcNodeID_ESC}
            {data-filter={data-filter-type=ALWAYS, max=1, min=0, offset=0}, i-signal-in-i-pdu=CtrlBitVector_ESC_Bit0_RMR}
            {data-filter={data-filter-type=ALWAYS, max=255, min=0, offset=0}, i-signal-in-i-pdu=usrData2_ESC}
            {data-filter={data-filter-type=ALWAYS, max=255, min=0, offset=0}, i-signal-in-i-pdu=usrData4_ESC_PN_Info1}
            {data-filter={data-filter-type=ALWAYS, max=255, min=0, offset=0}, i-signal-in-i-pdu=usrData5_ESC_PN_Info2}
            {data-filter={data-filter-type=ALWAYS, max=255, min=0, offset=0}, i-signal-in-i-pdu=usrData3_ESC}
          signal usrData1_ESC_Bit7_ECUSPEC_AWAKE: start 31, 1 bit, big-endian, init-value=0, base-type=uint8, compu {phys=raw for raw 0..1, 0=INACTIVE, 1=ACTIVE}, end-to-end-transformation-i-signal-props=data-ids=0, to Ecu_TPMS
          signal usrData1_ESC_Bit6_DIAGN_AWAKE: start 30, 1 bit, big-endian, init-value=0, base-type=uint8, compu {phys=raw for raw 0..1, 0=INACTIVE, 1=ACTIVE}, end-to-end-transformation-i-signal-props=data-ids=0, to Ecu_TPMS
          signal usrData1_ESC_Bit5_IGNITION_AWAKE: start 29, 1 bit, big-endian, init-value=0, base-type=uint8, compu {phys=raw for raw 0..1, 0=INACTIVE, 1=ACTIVE}, end-to-end-transformation-i-signal-props=data-ids=0, to Ecu_TPMS
          signal usrData1_ESC_Bit4_NETWORK_AWAKE: start 28, 1 bit, big-endian, init-value=0, base-type=uint8, compu {phys=raw for raw 0..1, 0=INACTIVE, 1=ACTIVE}, end-to-end-transformation-i-signal-props=data-ids=0, to Ecu_TPMS
          signal usrData1_ESC_Bit3_ECUSPEC_WAKEUP: start 27, 1 bit, big-endian, init-value=0, base-type=uint8, compu {phys=raw for raw 0..1, 0=INACTIVE, 1=ACTIVE}, end-to-end-transformation-i-signal-props=data-ids=0, to Ecu_TPMS
          signal usrData1_ESC_Bit2_NETWORK_WAKEUP: start 26, 1 bit, big-endian, init-value=0, base-type=uint8, compu {phys=raw for raw 0..1, 0=INACTIVE, 1=ACTIVE}, end-to-end-transformation-i-signal-props=data-ids=0, to Ecu_TPMS
          signal usrData1_ESC_Bit1_RESET_WAKEUP: start 25, 1 bit, big-endian, init-value=0, base-type=uint8, compu {phys=raw for raw 0..1, 0=INACTIVE, 1=ACTIVE}, end-to-end-transformation-i-signal-props=data-ids=0, to Ecu_TPMS
          signal CtrlBitVector_ESC_Bit7_Res: start 15, 1 bit, big-endian, init-value=0, base-type=uint8, compu {raw=phys for phys 0..1}, end-to-end-transformation-i-signal-props=data-ids=0, to Ecu_TPMS
          signal CtrlBitVector_ESC_Bit6_PNI: start 14, 1 bit, big-endian, init-value=0, base-type=uint8, compu {raw=phys for phys 0..1}, end-to-end-transformation-i-signal-props=data-ids=0, to Ecu_TPMS
          signal CtrlBitVector_ESC_Bit5_Res: start 13, 1 bit, big-endian, init-value=0, base-type=uint8, compu {raw=phys for phys 0..1}, end-to-end-transformation-i-signal-props=data-ids=0, to Ecu_TPMS
          signal CtrlBitVector_ESC_Bit4_ActWake: start 12, 1 bit, big-endian, init-value=0, base-type=uint8, compu {raw=phys for phys 0..1}, end-to-end-transformation-i-signal-props=data-ids=0, to Ecu_TPMS
          signal CtrlBitVector_ESC_Bit3_NMCoord: start 11, 1 bit, big-endian, init-value=0, base-type=uint8, compu {phys=raw for raw 0..1, 0=STARTOFSYNCHRONIZEDSHUTDOWNISNOTREQUESTEDBYMAINCOORDINATOR, 1=STARTOFSYNCHRONIZEDSHUTDOWNISREQUESTEDBYMAINCOORDINATOR}, end-to-end-transformation-i-signal-props=data-ids=0, to Ecu_TPMS
          signal CtrlBitVector_ESC_Bit2_Res: start 10, 1 bit, big-endian, init-value=0, base-type=uint8, compu {raw=phys for phys 0..1}, end-to-end-transformation-i-signal-props=data-ids=0, to Ecu_TPMS
          signal CtrlBitVector_ESC_Bit1_Res: start 9, 1 bit, big-endian, init-value=0, base-type=uint8, compu {raw=phys for phys 0..1}, end-to-end-transformation-i-signal-props=data-ids=0, to Ecu_TPMS
          signal usrData1_ESC_Bit0_IGN_WAKEUP: start 24, 1 bit, big-endian, init-value=0, base-type=uint8, compu {phys=raw for raw 0..1, 0=INACTIVE, 1=ACTIVE}, end-to-end-transformation-i-signal-props=data-ids=0, to Ecu_TPMS
          signal usrData0_ESC: start 23, 8 bit, big-endian, init-value=0, base-type=uint8, compu {phys=raw for raw 0..255, 0=USERDATAFORCURRENTVEHICLEWITHOUTPARTIALNETWORKING, 1=USERDATAFORCURRENTVEHICLEWITHPARTIALNETWORKING, 255=USERDATANOTUSED}, end-to-end-transformation-i-signal-props=data-ids=0, to Ecu_TPMS
          signal srcNodeID_ESC: start 7, 8 bit, big-endian, init-value=0, base-type=uint8, compu {raw=phys for phys 0..127}, end-to-end-transformation-i-signal-props=data-ids=0, to Ecu_TPMS
          signal CtrlBitVector_ESC_Bit0_RMR: start 8, 1 bit, big-endian, init-value=0, base-type=uint8, compu {raw=phys for phys 0..1}, end-to-end-transformation-i-signal-props=data-ids=0, to Ecu_TPMS
          signal usrData2_ESC: start 39, 8 bit, big-endian, init-value=0, base-type=uint8, compu {raw=phys for phys 0..255}, end-to-end-transformation-i-signal-props=data-ids=0, to Ecu_TPMS
          signal usrData4_ESC_PN_Info1: start 55, 8 bit, big-endian, init-value=0, base-type=uint8, compu {raw=phys for phys 0..255}, end-to-end-transformation-i-signal-props=data-ids=0, to Ecu_TPMS
          signal usrData5_ESC_PN_Info2: start 63, 8 bit, big-endian, init-value=0, base-type=uint8, compu {raw=phys for phys 0..255}, end-to-end-transformation-i-signal-props=data-ids=0, to Ecu_TPMS
          signal usrData3_ESC: start 47, 8 bit, big-endian, init-value=0, base-type=uint8, compu {raw=phys for phys 0..255}, end-to-end-transformation-i-signal-props=data-ids=0, to Ecu_TPMS
      frame FrameCan_NM_FCM: id 0x505, to Ecu_TPMS, frame-length=8, can-addressing-mode=STANDARD  # Networkmanagement message"
        carries pdu IPduISignal_NM_FCM: packing-byte-order=big-endian, start-position=7
        pdu IPduISignal_NM_FCM: length=8  # Networkmanagement message
          transmission-mode-conditions:
            {data-filter={data-filter-type=ALWAYS, max=1, min=0, offset=0}, i-signal-in-i-pdu=usrData1_FCM_Bit7_ECUSPEC_AWAKE}
            {data-filter={data-filter-type=ALWAYS, max=1, min=0, offset=0}, i-signal-in-i-pdu=usrData1_FCM_Bit6_DIAGN_AWAKE}
            {data-filter={data-filter-type=ALWAYS, max=1, min=0, offset=0}, i-signal-in-i-pdu=usrData1_FCM_Bit5_IGNITION_AWAKE}
            {data-filter={data-filter-type=ALWAYS, max=1, min=0, offset=0}, i-signal-in-i-pdu=usrData1_FCM_Bit4_NETWORK_AWAKE}
            {data-filter={data-filter-type=ALWAYS, max=1, min=0, offset=0}, i-signal-in-i-pdu=usrData1_FCM_Bit3_ECUSPEC_WAKEUP}
            {data-filter={data-filter-type=ALWAYS, max=1, min=0, offset=0}, i-signal-in-i-pdu=usrData1_FCM_Bit2_NETWORK_WAKEUP}
            {data-filter={data-filter-type=ALWAYS, max=1, min=0, offset=0}, i-signal-in-i-pdu=usrData1_FCM_Bit1_RESET_WAKEUP}
            {data-filter={data-filter-type=ALWAYS, max=1, min=0, offset=0}, i-signal-in-i-pdu=CtrlBitVector_FCM_Bit7_Res}
            {data-filter={data-filter-type=ALWAYS, max=1, min=0, offset=0}, i-signal-in-i-pdu=CtrlBitVector_FCM_Bit6_PNI}
            {data-filter={data-filter-type=ALWAYS, max=1, min=0, offset=0}, i-signal-in-i-pdu=CtrlBitVector_FCM_Bit5_Res}
            {data-filter={data-filter-type=ALWAYS, max=1, min=0, offset=0}, i-signal-in-i-pdu=CtrlBitVector_FCM_Bit4_ActWake}
            {data-filter={data-filter-type=ALWAYS, max=1, min=0, offset=0}, i-signal-in-i-pdu=CtrlBitVector_FCM_Bit3_NMCoord}
            {data-filter={data-filter-type=ALWAYS, max=1, min=0, offset=0}, i-signal-in-i-pdu=CtrlBitVector_FCM_Bit2_Res}
            {data-filter={data-filter-type=ALWAYS, max=1, min=0, offset=0}, i-signal-in-i-pdu=CtrlBitVector_FCM_Bit1_Res}
            {data-filter={data-filter-type=ALWAYS, max=1, min=0, offset=0}, i-signal-in-i-pdu=usrData1_FCM_Bit0_IGN_WAKEUP}
            {data-filter={data-filter-type=ALWAYS, max=255, min=0, offset=0}, i-signal-in-i-pdu=usrData0_FCM}
            {data-filter={data-filter-type=ALWAYS, max=127, min=0, offset=0}, i-signal-in-i-pdu=srcNodeID_FCM}
            {data-filter={data-filter-type=ALWAYS, max=1, min=0, offset=0}, i-signal-in-i-pdu=CtrlBitVector_FCM_Bit0_RMR}
            {data-filter={data-filter-type=ALWAYS, max=255, min=0, offset=0}, i-signal-in-i-pdu=usrData2_FCM}
            {data-filter={data-filter-type=ALWAYS, max=255, min=0, offset=0}, i-signal-in-i-pdu=usrData4_FCM_PN_Info1}
            {data-filter={data-filter-type=ALWAYS, max=255, min=0, offset=0}, i-signal-in-i-pdu=usrData5_FCM_PN_Info2}
            {data-filter={data-filter-type=ALWAYS, max=255, min=0, offset=0}, i-signal-in-i-pdu=usrData3_FCM}
          signal usrData1_FCM_Bit7_ECUSPEC_AWAKE: start 31, 1 bit, big-endian, init-value=0, base-type=uint8, compu {phys=raw for raw 0..1, 0=INACTIVE, 1=ACTIVE}, end-to-end-transformation-i-signal-props=data-ids=0, to Ecu_TPMS
          signal usrData1_FCM_Bit6_DIAGN_AWAKE: start 30, 1 bit, big-endian, init-value=0, base-type=uint8, compu {phys=raw for raw 0..1, 0=INACTIVE, 1=ACTIVE}, end-to-end-transformation-i-signal-props=data-ids=0, to Ecu_TPMS
          signal usrData1_FCM_Bit5_IGNITION_AWAKE: start 29, 1 bit, big-endian, init-value=0, base-type=uint8, compu {phys=raw for raw 0..1, 0=INACTIVE, 1=ACTIVE}, end-to-end-transformation-i-signal-props=data-ids=0, to Ecu_TPMS
          signal usrData1_FCM_Bit4_NETWORK_AWAKE: start 28, 1 bit, big-endian, init-value=0, base-type=uint8, compu {phys=raw for raw 0..1, 0=INACTIVE, 1=ACTIVE}, end-to-end-transformation-i-signal-props=data-ids=0, to Ecu_TPMS
          signal usrData1_FCM_Bit3_ECUSPEC_WAKEUP: start 27, 1 bit, big-endian, init-value=0, base-type=uint8, compu {phys=raw for raw 0..1, 0=INACTIVE, 1=ACTIVE}, end-to-end-transformation-i-signal-props=data-ids=0, to Ecu_TPMS
          signal usrData1_FCM_Bit2_NETWORK_WAKEUP: start 26, 1 bit, big-endian, init-value=0, base-type=uint8, compu {phys=raw for raw 0..1, 0=INACTIVE, 1=ACTIVE}, end-to-end-transformation-i-signal-props=data-ids=0, to Ecu_TPMS
          signal usrData1_FCM_Bit1_RESET_WAKEUP: start 25, 1 bit, big-endian, init-value=0, base-type=uint8, compu {phys=raw for raw 0..1, 0=INACTIVE, 1=ACTIVE}, end-to-end-transformation-i-signal-props=data-ids=0, to Ecu_TPMS
          signal CtrlBitVector_FCM_Bit7_Res: start 15, 1 bit, big-endian, init-value=0, base-type=uint8, compu {raw=phys for phys 0..1}, end-to-end-transformation-i-signal-props=data-ids=0, to Ecu_TPMS
          signal CtrlBitVector_FCM_Bit6_PNI: start 14, 1 bit, big-endian, init-value=0, base-type=uint8, compu {raw=phys for phys 0..1}, end-to-end-transformation-i-signal-props=data-ids=0, to Ecu_TPMS
          signal CtrlBitVector_FCM_Bit5_Res: start 13, 1 bit, big-endian, init-value=0, base-type=uint8, compu {raw=phys for phys 0..1}, end-to-end-transformation-i-signal-props=data-ids=0, to Ecu_TPMS
          signal CtrlBitVector_FCM_Bit4_ActWake: start 12, 1 bit, big-endian, init-value=0, base-type=uint8, compu {raw=phys for phys 0..1}, end-to-end-transformation-i-signal-props=data-ids=0, to Ecu_TPMS
          signal CtrlBitVector_FCM_Bit3_NMCoord: start 11, 1 bit, big-endian, init-value=0, base-type=uint8, compu {phys=raw for raw 0..1, 0=STARTOFSYNCHRONIZEDSHUTDOWNISNOTREQUESTEDBYMAINCOORDINATOR, 1=STARTOFSYNCHRONIZEDSHUTDOWNISREQUESTEDBYMAINCOORDINATOR}, end-to-end-transformation-i-signal-props=data-ids=0, to Ecu_TPMS
          signal CtrlBitVector_FCM_Bit2_Res: start 10, 1 bit, big-endian, init-value=0, base-type=uint8, compu {raw=phys for phys 0..1}, end-to-end-transformation-i-signal-props=data-ids=0, to Ecu_TPMS
          signal CtrlBitVector_FCM_Bit1_Res: start 9, 1 bit, big-endian, init-value=0, base-type=uint8, compu {raw=phys for phys 0..1}, end-to-end-transformation-i-signal-props=data-ids=0, to Ecu_TPMS
          signal usrData1_FCM_Bit0_IGN_WAKEUP: start 24, 1 bit, big-endian, init-value=0, base-type=uint8, compu {phys=raw for raw 0..1, 0=INACTIVE, 1=ACTIVE}, end-to-end-transformation-i-signal-props=data-ids=0, to Ecu_TPMS
          signal usrData0_FCM: start 23, 8 bit, big-endian, init-value=0, base-type=uint8, compu {phys=raw for raw 0..255, 0=USERDATAFORCURRENTVEHICLEWITHOUTPARTIALNETWORKING, 1=USERDATAFORCURRENTVEHICLEWITHPARTIALNETWORKING, 255=USERDATANOTUSED}, end-to-end-transformation-i-signal-props=data-ids=0, to Ecu_TPMS
          signal srcNodeID_FCM: start 7, 8 bit, big-endian, init-value=0, base-type=uint8, compu {raw=phys for phys 0..127}, end-to-end-transformation-i-signal-props=data-ids=0, to Ecu_TPMS
          signal CtrlBitVector_FCM_Bit0_RMR: start 8, 1 bit, big-endian, init-value=0, base-type=uint8, compu {raw=phys for phys 0..1}, end-to-end-transformation-i-signal-props=data-ids=0, to Ecu_TPMS
          signal usrData2_FCM: start 39, 8 bit, big-endian, init-value=0, base-type=uint8, compu {raw=phys for phys 0..255}, end-to-end-transformation-i-signal-props=data-ids=0, to Ecu_TPMS
          signal usrData4_FCM_PN_Info1: start 55, 8 bit, big-endian, init-value=0, base-type=uint8, compu {raw=phys for phys 0..255}, end-to-end-transformation-i-signal-props=data-ids=0, to Ecu_TPMS
          signal usrData5_FCM_PN_Info2: start 63, 8 bit, big-endian, init-value=0, base-type=uint8, compu {raw=phys for phys 0..255}, end-to-end-transformation-i-signal-props=data-ids=0, to Ecu_TPMS
          signal usrData3_FCM: start 47, 8 bit, big-endian, init-value=0, base-type=uint8, compu {raw=phys for phys 0..255}, end-to-end-transformation-i-signal-props=data-ids=0, to Ecu_TPMS
      frame FrameCan_NM_VCU: id 0x504, to Ecu_TPMS, frame-length=8, can-addressing-mode=STANDARD  # Networkmanagement message"
        carries pdu IPduISignal_NM_VCU: packing-byte-order=big-endian, start-position=7
        pdu IPduISignal_NM_VCU: length=8  # Networkmanagement message
          transmission-mode-conditions:
            {data-filter={data-filter-type=ALWAYS, max=1, min=0, offset=0}, i-signal-in-i-pdu=usrData1_VCU_Bit7_ECUSPEC_AWAKE}
            {data-filter={data-filter-type=ALWAYS, max=1, min=0, offset=0}, i-signal-in-i-pdu=usrData1_VCU_Bit6_DIAGN_AWAKE}
            {data-filter={data-filter-type=ALWAYS, max=1, min=0, offset=0}, i-signal-in-i-pdu=usrData1_VCU_Bit5_IGNITION_AWAKE}
            {data-filter={data-filter-type=ALWAYS, max=1, min=0, offset=0}, i-signal-in-i-pdu=usrData1_VCU_Bit4_NETWORK_AWAKE}
            {data-filter={data-filter-type=ALWAYS, max=1, min=0, offset=0}, i-signal-in-i-pdu=usrData1_VCU_Bit3_ECUSPEC_WAKEUP}
            {data-filter={data-filter-type=ALWAYS, max=1, min=0, offset=0}, i-signal-in-i-pdu=usrData1_VCU_Bit2_NETWORK_WAKEUP}
            {data-filter={data-filter-type=ALWAYS, max=1, min=0, offset=0}, i-signal-in-i-pdu=usrData1_VCU_Bit1_RESET_WAKEUP}
            {data-filter={data-filter-type=ALWAYS, max=1, min=0, offset=0}, i-signal-in-i-pdu=CtrlBitVector_VCU_Bit7_Res}
            {data-filter={data-filter-type=ALWAYS, max=1, min=0, offset=0}, i-signal-in-i-pdu=CtrlBitVector_VCU_Bit6_PNI}
            {data-filter={data-filter-type=ALWAYS, max=1, min=0, offset=0}, i-signal-in-i-pdu=CtrlBitVector_VCU_Bit5_Res}
            {data-filter={data-filter-type=ALWAYS, max=1, min=0, offset=0}, i-signal-in-i-pdu=CtrlBitVector_VCU_Bit4_ActWake}
            {data-filter={data-filter-type=ALWAYS, max=1, min=0, offset=0}, i-signal-in-i-pdu=CtrlBitVector_VCU_Bit3_NMCoord}
            {data-filter={data-filter-type=ALWAYS, max=1, min=0, offset=0}, i-signal-in-i-pdu=CtrlBitVector_VCU_Bit2_Res}
            {data-filter={data-filter-type=ALWAYS, max=1, min=0, offset=0}, i-signal-in-i-pdu=CtrlBitVector_VCU_Bit1_Res}
            {data-filter={data-filter-type=ALWAYS, max=1, min=0, offset=0}, i-signal-in-i-pdu=usrData1_VCU_Bit0_IGN_WAKEUP}
            {data-filter={data-filter-type=ALWAYS, max=255, min=0, offset=0}, i-signal-in-i-pdu=usrData0_VCU}
            {data-filter={data-filter-type=ALWAYS, max=127, min=0, offset=0}, i-signal-in-i-pdu=srcNodeID_VCU}
            {data-filter={data-filter-type=ALWAYS, max=1, min=0, offset=0}, i-signal-in-i-pdu=CtrlBitVector_VCU_Bit0_RMR}
            {data-filter={data-filter-type=ALWAYS, max=255, min=0, offset=0}, i-signal-in-i-pdu=usrData2_VCU}
            {data-filter={data-filter-type=ALWAYS, max=255, min=0, offset=0}, i-signal-in-i-pdu=usrData4_VCU_PN_Info1}
            {data-filter={data-filter-type=ALWAYS, max=255, min=0, offset=0}, i-signal-in-i-pdu=usrData5_VCU_PN_Info2}
            {data-filter={data-filter-type=ALWAYS, max=255, min=0, offset=0}, i-signal-in-i-pdu=usrData3_VCU}
          signal usrData1_VCU_Bit7_ECUSPEC_AWAKE: start 31, 1 bit, big-endian, init-value=0, base-type=uint8, compu {phys=raw for raw 0..1, 0=INACTIVE, 1=ACTIVE}, end-to-end-transformation-i-signal-props=data-ids=0, to Ecu_TPMS
          signal usrData1_VCU_Bit6_DIAGN_AWAKE: start 30, 1 bit, big-endian, init-value=0, base-type=uint8, compu {phys=raw for raw 0..1, 0=INACTIVE, 1=ACTIVE}, end-to-end-transformation-i-signal-props=data-ids=0, to Ecu_TPMS
          signal usrData1_VCU_Bit5_IGNITION_AWAKE: start 29, 1 bit, big-endian, init-value=0, base-type=uint8, compu {phys=raw for raw 0..1, 0=INACTIVE, 1=ACTIVE}, end-to-end-transformation-i-signal-props=data-ids=0, to Ecu_TPMS
          signal usrData1_VCU_Bit4_NETWORK_AWAKE: start 28, 1 bit, big-endian, init-value=0, base-type=uint8, compu {phys=raw for raw 0..1, 0=INACTIVE, 1=ACTIVE}, end-to-end-transformation-i-signal-props=data-ids=0, to Ecu_TPMS
          signal usrData1_VCU_Bit3_ECUSPEC_WAKEUP: start 27, 1 bit, big-endian, init-value=0, base-type=uint8, compu {phys=raw for raw 0..1, 0=INACTIVE, 1=ACTIVE}, end-to-end-transformation-i-signal-props=data-ids=0, to Ecu_TPMS
          signal usrData1_VCU_Bit2_NETWORK_WAKEUP: start 26, 1 bit, big-endian, init-value=0, base-type=uint8, compu {phys=raw for raw 0..1, 0=INACTIVE, 1=ACTIVE}, end-to-end-transformation-i-signal-props=data-ids=0, to Ecu_TPMS
          signal usrData1_VCU_Bit1_RESET_WAKEUP: start 25, 1 bit, big-endian, init-value=0, base-type=uint8, compu {phys=raw for raw 0..1, 0=INACTIVE, 1=ACTIVE}, end-to-end-transformation-i-signal-props=data-ids=0, to Ecu_TPMS
          signal CtrlBitVector_VCU_Bit7_Res: start 15, 1 bit, big-endian, init-value=0, base-type=uint8, compu {raw=phys for phys 0..1}, end-to-end-transformation-i-signal-props=data-ids=0, to Ecu_TPMS
          signal CtrlBitVector_VCU_Bit6_PNI: start 14, 1 bit, big-endian, init-value=0, base-type=uint8, compu {raw=phys for phys 0..1}, end-to-end-transformation-i-signal-props=data-ids=0, to Ecu_TPMS
          signal CtrlBitVector_VCU_Bit5_Res: start 13, 1 bit, big-endian, init-value=0, base-type=uint8, compu {raw=phys for phys 0..1}, end-to-end-transformation-i-signal-props=data-ids=0, to Ecu_TPMS
          signal CtrlBitVector_VCU_Bit4_ActWake: start 12, 1 bit, big-endian, init-value=0, base-type=uint8, compu {raw=phys for phys 0..1}, end-to-end-transformation-i-signal-props=data-ids=0, to Ecu_TPMS
          signal CtrlBitVector_VCU_Bit3_NMCoord: start 11, 1 bit, big-endian, init-value=0, base-type=uint8, compu {phys=raw for raw 0..1, 0=STARTOFSYNCHRONIZEDSHUTDOWNISNOTREQUESTEDBYMAINCOORDINATOR, 1=STARTOFSYNCHRONIZEDSHUTDOWNISREQUESTEDBYMAINCOORDINATOR}, end-to-end-transformation-i-signal-props=data-ids=0, to Ecu_TPMS
          signal CtrlBitVector_VCU_Bit2_Res: start 10, 1 bit, big-endian, init-value=0, base-type=uint8, compu {raw=phys for phys 0..1}, end-to-end-transformation-i-signal-props=data-ids=0, to Ecu_TPMS
          signal CtrlBitVector_VCU_Bit1_Res: start 9, 1 bit, big-endian, init-value=0, base-type=uint8, compu {raw=phys for phys 0..1}, end-to-end-transformation-i-signal-props=data-ids=0, to Ecu_TPMS
          signal usrData1_VCU_Bit0_IGN_WAKEUP: start 24, 1 bit, big-endian, init-value=0, base-type=uint8, compu {phys=raw for raw 0..1, 0=INACTIVE, 1=ACTIVE}, end-to-end-transformation-i-signal-props=data-ids=0, to Ecu_TPMS
          signal usrData0_VCU: start 23, 8 bit, big-endian, init-value=0, base-type=uint8, compu {phys=raw for raw 0..255, 0=USERDATAFORCURRENTVEHICLEWITHOUTPARTIALNETWORKING, 1=USERDATAFORCURRENTVEHICLEWITHPARTIALNETWORKING, 255=USERDATANOTUSED}, end-to-end-transformation-i-signal-props=data-ids=0, to Ecu_TPMS
          signal srcNodeID_VCU: start 7, 8 bit, big-endian, init-value=0, base-type=uint8, compu {raw=phys for phys 0..127}, end-to-end-transformation-i-signal-props=data-ids=0, to Ecu_TPMS
          signal CtrlBitVector_VCU_Bit0_RMR: start 8, 1 bit, big-endian, init-value=0, base-type=uint8, compu {raw=phys for phys 0..1}, end-to-end-transformation-i-signal-props=data-ids=0, to Ecu_TPMS
          signal usrData2_VCU: start 39, 8 bit, big-endian, init-value=0, base-type=uint8, compu {raw=phys for phys 0..255}, end-to-end-transformation-i-signal-props=data-ids=0, to Ecu_TPMS
          signal usrData4_VCU_PN_Info1: start 55, 8 bit, big-endian, init-value=0, base-type=uint8, compu {raw=phys for phys 0..255}, end-to-end-transformation-i-signal-props=data-ids=0, to Ecu_TPMS
          signal usrData5_VCU_PN_Info2: start 63, 8 bit, big-endian, init-value=0, base-type=uint8, compu {raw=phys for phys 0..255}, end-to-end-transformation-i-signal-props=data-ids=0, to Ecu_TPMS
          signal usrData3_VCU: start 47, 8 bit, big-endian, init-value=0, base-type=uint8, compu {raw=phys for phys 0..255}, end-to-end-transformation-i-signal-props=data-ids=0, to Ecu_TPMS
      frame FrameCan_NM_iBooster: id 0x51F, to Ecu_TPMS, frame-length=8, can-addressing-mode=STANDARD  # Networkmanagement message"
        carries pdu IPduISignal_NM_iBooster: packing-byte-order=big-endian, start-position=7
        pdu IPduISignal_NM_iBooster: length=8  # Networkmanagement message
          transmission-mode-conditions:
            {data-filter={data-filter-type=ALWAYS, max=1, min=0, offset=0}, i-signal-in-i-pdu=usrData1_iBo_Bit7_ECUSPEC_AWAKE}
            {data-filter={data-filter-type=ALWAYS, max=1, min=0, offset=0}, i-signal-in-i-pdu=usrData1_iBo_Bit6_DIAGN_AWAKE}
            {data-filter={data-filter-type=ALWAYS, max=1, min=0, offset=0}, i-signal-in-i-pdu=usrData1_iBo_Bit5_IGNITION_AWAKE}
            {data-filter={data-filter-type=ALWAYS, max=1, min=0, offset=0}, i-signal-in-i-pdu=usrData1_iBo_Bit4_NETWORK_AWAKE}
            {data-filter={data-filter-type=ALWAYS, max=1, min=0, offset=0}, i-signal-in-i-pdu=usrData1_iBo_Bit3_ECUSPEC_WAKEUP}
            {data-filter={data-filter-type=ALWAYS, max=1, min=0, offset=0}, i-signal-in-i-pdu=usrData1_iBo_Bit2_NETWORK_WAKEUP}
            {data-filter={data-filter-type=ALWAYS, max=1, min=0, offset=0}, i-signal-in-i-pdu=usrData1_iBo_Bit1_RESET_WAKEUP}
            {data-filter={data-filter-type=ALWAYS, max=1, min=0, offset=0}, i-signal-in-i-pdu=CtrlBitVector_iBo_Bit7_Res}
            {data-filter={data-filter-type=ALWAYS, max=1, min=0, offset=0}, i-signal-in-i-pdu=CtrlBitVector_iBo_Bit6_PNI}
            {data-filter={data-filter-type=ALWAYS, max=1, min=0, offset=0}, i-signal-in-i-pdu=CtrlBitVector_iBo_Bit5_Res}
            {data-filter={data-filter-type=ALWAYS, max=1, min=0, offset=0}, i-signal-in-i-pdu=CtrlBitVector_iBo_Bit4_ActWake}
            {data-filter={data-filter-type=ALWAYS, max=1, min=0, offset=0}, i-signal-in-i-pdu=CtrlBitVector_iBo_Bit3_NMCoord}
            {data-filter={data-filter-type=ALWAYS, max=1, min=0, offset=0}, i-signal-in-i-pdu=CtrlBitVector_iBo_Bit2_Res}
            {data-filter={data-filter-type=ALWAYS, max=1, min=0, offset=0}, i-signal-in-i-pdu=CtrlBitVector_iBo_Bit1_Res}
            {data-filter={data-filter-type=ALWAYS, max=1, min=0, offset=0}, i-signal-in-i-pdu=usrData1_iBo_Bit0_IGN_WAKEUP}
            {data-filter={data-filter-type=ALWAYS, max=255, min=0, offset=0}, i-signal-in-i-pdu=usrData0_iBo}
            {data-filter={data-filter-type=ALWAYS, max=127, min=0, offset=0}, i-signal-in-i-pdu=srcNodeID_iBo}
            {data-filter={data-filter-type=ALWAYS, max=1, min=0, offset=0}, i-signal-in-i-pdu=CtrlBitVector_iBo_Bit0_RMR}
            {data-filter={data-filter-type=ALWAYS, max=255, min=0, offset=0}, i-signal-in-i-pdu=usrData2_iBo}
            {data-filter={data-filter-type=ALWAYS, max=255, min=0, offset=0}, i-signal-in-i-pdu=usrData4_iBo_PN_Info1}
            {data-filter={data-filter-type=ALWAYS, max=255, min=0, offset=0}, i-signal-in-i-pdu=usrData5_iBo_PN_Info2}
            {data-filter={data-filter-type=ALWAYS, max=255, min=0, offset=0}, i-signal-in-i-pdu=usrData3_iBo}
          signal usrData1_iBo_Bit7_ECUSPEC_AWAKE: start 31, 1 bit, big-endian, init-value=0, base-type=uint8, compu {phys=raw for raw 0..1, 0=INACTIVE, 1=ACTIVE}, end-to-end-transformation-i-signal-props=data-ids=0, to Ecu_TPMS
          signal usrData1_iBo_Bit6_DIAGN_AWAKE: start 30, 1 bit, big-endian, init-value=0, base-type=uint8, compu {phys=raw for raw 0..1, 0=INACTIVE, 1=ACTIVE}, end-to-end-transformation-i-signal-props=data-ids=0, to Ecu_TPMS
          signal usrData1_iBo_Bit5_IGNITION_AWAKE: start 29, 1 bit, big-endian, init-value=0, base-type=uint8, compu {phys=raw for raw 0..1, 0=INACTIVE, 1=ACTIVE}, end-to-end-transformation-i-signal-props=data-ids=0, to Ecu_TPMS
          signal usrData1_iBo_Bit4_NETWORK_AWAKE: start 28, 1 bit, big-endian, init-value=0, base-type=uint8, compu {phys=raw for raw 0..1, 0=INACTIVE, 1=ACTIVE}, end-to-end-transformation-i-signal-props=data-ids=0, to Ecu_TPMS
          signal usrData1_iBo_Bit3_ECUSPEC_WAKEUP: start 27, 1 bit, big-endian, init-value=0, base-type=uint8, compu {phys=raw for raw 0..1, 0=INACTIVE, 1=ACTIVE}, end-to-end-transformation-i-signal-props=data-ids=0, to Ecu_TPMS
          signal usrData1_iBo_Bit2_NETWORK_WAKEUP: start 26, 1 bit, big-endian, init-value=0, base-type=uint8, compu {phys=raw for raw 0..1, 0=INACTIVE, 1=ACTIVE}, end-to-end-transformation-i-signal-props=data-ids=0, to Ecu_TPMS
          signal usrData1_iBo_Bit1_RESET_WAKEUP: start 25, 1 bit, big-endian, init-value=0, base-type=uint8, compu {phys=raw for raw 0..1, 0=INACTIVE, 1=ACTIVE}, end-to-end-transformation-i-signal-props=data-ids=0, to Ecu_TPMS
          signal CtrlBitVector_iBo_Bit7_Res: start 15, 1 bit, big-endian, init-value=0, base-type=uint8, compu {raw=phys for phys 0..1}, end-to-end-transformation-i-signal-props=data-ids=0, to Ecu_TPMS
          signal CtrlBitVector_iBo_Bit6_PNI: start 14, 1 bit, big-endian, init-value=0, base-type=uint8, compu {raw=phys for phys 0..1}, end-to-end-transformation-i-signal-props=data-ids=0, to Ecu_TPMS
          signal CtrlBitVector_iBo_Bit5_Res: start 13, 1 bit, big-endian, init-value=0, base-type=uint8, compu {raw=phys for phys 0..1}, end-to-end-transformation-i-signal-props=data-ids=0, to Ecu_TPMS
          signal CtrlBitVector_iBo_Bit4_ActWake: start 12, 1 bit, big-endian, init-value=0, base-type=uint8, compu {raw=phys for phys 0..1}, end-to-end-transformation-i-signal-props=data-ids=0, to Ecu_TPMS
          signal CtrlBitVector_iBo_Bit3_NMCoord: start 11, 1 bit, big-endian, init-value=0, base-type=uint8, compu {phys=raw for raw 0..1, 0=STARTOFSYNCHRONIZEDSHUTDOWNISNOTREQUESTEDBYMAINCOORDINATOR, 1=STARTOFSYNCHRONIZEDSHUTDOWNISREQUESTEDBYMAINCOORDINATOR}, end-to-end-transformation-i-signal-props=data-ids=0, to Ecu_TPMS
          signal CtrlBitVector_iBo_Bit2_Res: start 10, 1 bit, big-endian, init-value=0, base-type=uint8, compu {raw=phys for phys 0..1}, end-to-end-transformation-i-signal-props=data-ids=0, to Ecu_TPMS
          signal CtrlBitVector_iBo_Bit1_Res: start 9, 1 bit, big-endian, init-value=0, base-type=uint8, compu {raw=phys for phys 0..1}, end-to-end-transformation-i-signal-props=data-ids=0, to Ecu_TPMS
          signal usrData1_iBo_Bit0_IGN_WAKEUP: start 24, 1 bit, big-endian, init-value=0, base-type=uint8, compu {phys=raw for raw 0..1, 0=INACTIVE, 1=ACTIVE}, end-to-end-transformation-i-signal-props=data-ids=0, to Ecu_TPMS
          signal usrData0_iBo: start 23, 8 bit, big-endian, init-value=0, base-type=uint8, compu {phys=raw for raw 0..255, 0=USERDATAFORCURRENTVEHICLEWITHOUTPARTIALNETWORKING, 1=USERDATAFORCURRENTVEHICLEWITHPARTIALNETWORKING, 255=USERDATANOTUSED}, end-to-end-transformation-i-signal-props=data-ids=0, to Ecu_TPMS
          signal srcNodeID_iBo: start 7, 8 bit, big-endian, init-value=0, base-type=uint8, compu {raw=phys for phys 0..127}, end-to-end-transformation-i-signal-props=data-ids=0, to Ecu_TPMS
          signal CtrlBitVector_iBo_Bit0_RMR: start 8, 1 bit, big-endian, init-value=0, base-type=uint8, compu {raw=phys for phys 0..1}, end-to-end-transformation-i-signal-props=data-ids=0, to Ecu_TPMS
          signal usrData2_iBo: start 39, 8 bit, big-endian, init-value=0, base-type=uint8, compu {raw=phys for phys 0..255}, end-to-end-transformation-i-signal-props=data-ids=0, to Ecu_TPMS
          signal usrData4_iBo_PN_Info1: start 55, 8 bit, big-endian, init-value=0, base-type=uint8, compu {raw=phys for phys 0..255}, end-to-end-transformation-i-signal-props=data-ids=0, to Ecu_TPMS
          signal usrData5_iBo_PN_Info2: start 63, 8 bit, big-endian, init-value=0, base-type=uint8, compu {raw=phys for phys 0..255}, end-to-end-transformation-i-signal-props=data-ids=0, to Ecu_TPMS
          signal usrData3_iBo: start 47, 8 bit, big-endian, init-value=0, base-type=uint8, compu {raw=phys for phys 0..255}, end-to-end-transformation-i-signal-props=data-ids=0, to Ecu_TPMS
      frame FrameCan_TBOX_01_OTA: id 0x315, to Ecu_TPMS, frame-length=16, can-addressing-mode=STANDARD, can-fd-frame-support=false, can-frame-rx-behavior=CAN-FD
        carries pdu IPduISignal_TBOX_01_OTA: packing-byte-order=big-endian, start-position=7
        pdu IPduISignal_TBOX_01_OTA: length=16, transmission-mode-false-timing=cyclic-timing={time-offset=0.0, time-period=0.5}, transmission-mode-true-timing=cyclic-timing={time-offset=0.0, time-period=0.5}
          transmission-mode-conditions:
            {data-filter={data-filter-type=ALWAYS, max=0, min=0, offset=0}, i-signal-in-i-pdu=TBOX_OTA_WakeupStatus}
            {data-filter={data-filter-type=ALWAYS, max=255, min=0, offset=0}, i-signal-in-i-pdu=ALIVE_TBOX_01}
            {data-filter={data-filter-type=NEW-IS-WITHIN, max=65535, min=0, offset=0}, i-signal-in-i-pdu=CRC_TBOX_01}
            {data-filter={data-filter-type=ALWAYS, max=15, min=0, offset=0}, i-signal-in-i-pdu=TBOX_OTA_Status}
          signal TBOX_OTA_WakeupStatus: start 99, 2 bit, big-endian, init-value=0, base-type=uint8, compu {phys=raw for raw 0, 0=INITIAL, 1=ACTIVE, 2=RESERVED, 3=INVALID}, end-to-end-transformation-i-signal-props=data-ids=0, to Ecu_TPMS  # it is a status of wake up type(OTA), TBOX shall send this signal when wakeup network for OTA until vehicle sleep"
          signal ALIVE_TBOX_01: start 23, 8 bit, big-endian, init-value=0, base-type=uint8, compu {raw=phys for phys 0..255}, end-to-end-transformation-i-signal-props=data-ids=0, to Ecu_TPMS  # Alive Counter"
          signal CRC_TBOX_01: start 7, 16 bit, big-endian, init-value=0, base-type=uint16, compu {raw=phys for phys 0..65535}, end-to-end-transformation-i-signal-props=data-ids=0, to Ecu_TPMS  # DataID=0x004F. Checksum calculation accordig CAN Specification. Cyclic Redundancy Check"
          signal TBOX_OTA_Status: start 103, 4 bit, big-endian, init-value=0, base-type=uint8, compu {phys=raw for raw 0..15, 11..14=RESERVED, 15=INVALID, 0=INITIAL, 1=NEWVERSIONAVAILABLE, 2=DOWNLOADING, 3=PRE_FLASHING, 4=PAUSEDOWNLOADING, 5=DOWNLOADERROR, 6=FLASHING, 7=OTAERROR, 8=ROLLBACK, 9=IDLE, 10=RESERVED}, end-to-end-transformation-i-signal-props=data-ids=0, to Ecu_TPMS  # TBOX send OTA status to all CANFD ECUs, OTA status is a statusmachine of OTA process"
      frame FrameCan_TBOX_02_TIME: id 0x2F8, to Ecu_TPMS, frame-length=20, can-addressing-mode=STANDARD, can-fd-frame-support=false, can-frame-rx-behavior=CAN-FD  # Time and Date information"
        carries pdu IPduISignal_TBOX_02_TIME: packing-byte-order=big-endian, start-position=7
        pdu IPduISignal_TBOX_02_TIME: length=20, transmission-mode-false-timing=cyclic-timing={time-offset=0.0, time-period=1.0}, transmission-mode-true-timing=cyclic-timing={time-offset=0.0, time-period=1.0}  # Time and Date information
          transmission-mode-conditions:
            {data-filter={data-filter-type=ALWAYS, max=255, min=0, offset=0}, i-signal-in-i-pdu=ALIVE_TBOX_02}
            {data-filter={data-filter-type=NEW-IS-WITHIN, max=65535, min=0, offset=0}, i-signal-in-i-pdu=CRC_TBOX_02}
            {data-filter={data-filter-type=ALWAYS, max=23, min=0, offset=0}, i-signal-in-i-pdu=TBOX_CrtTi_Hr}
            {data-filter={data-filter-type=ALWAYS, max=59, min=0, offset=0}, i-signal-in-i-pdu=TBOX_CrtTi_Mins}
            {data-filter={data-filter-type=ALWAYS, max=59, min=0, offset=0}, i-signal-in-i-pdu=TBOX_CrtTi_Sec}
            {data-filter={data-filter-type=ALWAYS, max=30, min=0, offset=1}, i-signal-in-i-pdu=TBOX_CrtTi_Day}
            {data-filter={data-filter-type=ALWAYS, max=11, min=0, offset=1}, i-signal-in-i-pdu=TBOX_CrtTi_Mth}
            {data-filter={data-filter-type=ALWAYS, max=255, min=0, offset=2015}, i-signal-in-i-pdu=TBOX_CrtTi_Yr}
            {data-filter={data-filter-type=ALWAYS, max=127, min=0}, i-signal-in-i-pdu=TBOX_ZoneT}
          signal ALIVE_TBOX_02: start 23, 8 bit, big-endian, init-value=0, base-type=uint8, compu {raw=phys for phys 0..255}, end-to-end-transformation-i-signal-props=data-ids=0, to Ecu_TPMS  # Alive Counter"
          signal CRC_TBOX_02: start 7, 16 bit, big-endian, init-value=0, base-type=uint16, compu {raw=phys for phys 0..65535}, end-to-end-transformation-i-signal-props=data-ids=0, to Ecu_TPMS  # DataID=0x0050. Checksum calculation accordig CAN Specification. Cyclic Redundancy Check"
          signal TBOX_CrtTi_Hr: start 119, 5 bit, big-endian, init-value=0, base-type=uint8, compu {raw=phys for phys 0..23; unit h}, end-to-end-transformation-i-signal-props=data-ids=0, to Ecu_TPMS  # Current hour information "
          signal TBOX_CrtTi_Mins: start 111, 6 bit, big-endian, init-value=0, base-type=uint8, compu {raw=phys for phys 0..59; unit min}, end-to-end-transformation-i-signal-props=data-ids=0, to Ecu_TPMS  # Current minutes information "
          signal TBOX_CrtTi_Sec: start 103, 6 bit, big-endian, init-value=0, base-type=uint8, compu {raw=phys for phys 0..59; unit s}, end-to-end-transformation-i-signal-props=data-ids=0, to Ecu_TPMS  # Current seconds information"
          signal TBOX_CrtTi_Day: start 127, 5 bit, big-endian, init-value=0, base-type=uint8, compu {raw=phys-1 for phys 1..31; unit d}, end-to-end-transformation-i-signal-props=data-ids=0, to Ecu_TPMS  # Current Day information."
          signal TBOX_CrtTi_Mth: start 135, 4 bit, big-endian, init-value=0, base-type=uint8, compu {raw=phys-1 for phys 1..12; unit mR}, end-to-end-transformation-i-signal-props=data-ids=0, to Ecu_TPMS  # Current month information"
          signal TBOX_CrtTi_Yr: start 143, 8 bit, big-endian, init-value=0, base-type=uint8, compu {raw=phys-2015 for phys 2015..2270; unit y}, end-to-end-transformation-i-signal-props=data-ids=0, to Ecu_TPMS  # Current year information"
          signal TBOX_ZoneT: start 151, 7 bit, big-endian, init-value=48, base-type=uint8, compu {raw=phys/15+48 for phys -720..1185; unit min}, end-to-end-transformation-i-signal-props=data-ids=0, to Ecu_TPMS  # Summer or Winter time information "
      frame FrameCan_TCC_02: id 0x340, to Ecu_TPMS, frame-length=48, can-addressing-mode=STANDARD, can-fd-frame-support=false, can-frame-rx-behavior=CAN-FD
        carries pdu IPduISignal_TCC_02: packing-byte-order=big-endian, start-position=7
        pdu IPduISignal_TCC_02: length=48, transmission-mode-false-timing=cyclic-timing={time-offset=0.0, time-period=0.1}, transmission-mode-true-timing=cyclic-timing={time-offset=0.0, time-period=0.1}
          transmission-mode-conditions:
            {data-filter={data-filter-type=ALWAYS, max=3, min=0, offset=0}, i-signal-in-i-pdu=TCC_ByPassFlap_error}
            {data-filter={data-filter-type=ALWAYS, max=3, min=0, offset=0}, i-signal-in-i-pdu=TCC_RecircFlap_error}
            {data-filter={data-filter-type=ALWAYS, max=3, min=0, offset=0}, i-signal-in-i-pdu=TCC_ModeFlap_error}
            {data-filter={data-filter-type=ALWAYS, max=3, min=0, offset=0}, i-signal-in-i-pdu=TCC_Blower_Error}
            {data-filter={data-filter-type=ALWAYS, max=7, min=0, offset=0}, i-signal-in-i-pdu=TCC_HVAC_AirDistributionMode}
            {data-filter={data-filter-type=ALWAYS, max=255, min=0, offset=0}, i-signal-in-i-pdu=TCC_HV_Compressor_Availability}
            {data-filter={data-filter-type=ALWAYS, max=3, min=0, offset=0}, i-signal-in-i-pdu=TCC_HV_Compressor_error}
            {data-filter={data-filter-type=ALWAYS, max=255, min=0, offset=0}, i-signal-in-i-pdu=TCC_HV_Compressor_power}
            {data-filter={data-filter-type=ALWAYS, max=255, min=0, offset=0}, i-signal-in-i-pdu=TCC_HV_PTC_HVAC_Availability}
            {data-filter={data-filter-type=ALWAYS, max=3, min=0, offset=0}, i-signal-in-i-pdu=TCC_HV_PTC_HVAC_error}
            {data-filter={data-filter-type=NEW-IS-WITHIN, max=128, min=0, offset=0}, i-signal-in-i-pdu=TCC_HV_PTC_HVAC_power}
            {data-filter={data-filter-type=ALWAYS, max=3, min=0, offset=0}, i-signal-in-i-pdu=TCC_AGM_error}
            {data-filter={data-filter-type=ALWAYS, max=3, min=0, offset=0}, i-signal-in-i-pdu=TCC_EFAN_error}
            {data-filter={data-filter-type=ALWAYS, max=255, min=0, offset=0}, i-signal-in-i-pdu=TCC_HV_PTC_Battery_Availability}
            {data-filter={data-filter-type=ALWAYS, max=3, min=0, offset=0}, i-signal-in-i-pdu=TCC_HV_PTC_Battery_error}
            {data-filter={data-filter-type=ALWAYS, max=70, min=0, offset=0}, i-signal-in-i-pdu=TCC_HV_PTC_Battery_power}
            {data-filter={data-filter-type=ALWAYS, max=3, min=0, offset=0}, i-signal-in-i-pdu=TCC_WAPU_EDU_Error}
            {data-filter={data-filter-type=ALWAYS, max=3, min=0, offset=0}, i-signal-in-i-pdu=TCC_RSV_EDU_Error}
            {data-filter={data-filter-type=ALWAYS, max=3, min=0, offset=0}, i-signal-in-i-pdu=TCC_CoolantTempEDURear_IN_error}
            {data-filter={data-filter-type=ALWAYS, max=3, min=0, offset=0}, i-signal-in-i-pdu=TCC_CoolantTempEDUFront_IN_error}
            {data-filter={data-filter-type=ALWAYS, max=3, min=0, offset=0}, i-signal-in-i-pdu=TCC_EDU_Cooling_error}
            {data-filter={data-filter-type=ALWAYS, max=165, min=0}, i-signal-in-i-pdu=TCC_CoolantTempIPU_IN}
            {data-filter={data-filter-type=ALWAYS, max=3, min=0, offset=0}, i-signal-in-i-pdu=TCC_STAT_Defrost}
            {data-filter={data-filter-type=ALWAYS, max=3, min=0, offset=0}, i-signal-in-i-pdu=TCC_STAT_Sync}
            {data-filter={data-filter-type=ALWAYS, max=3, min=0, offset=0}, i-signal-in-i-pdu=TCC_STAT_Recirc}
            {data-filter={data-filter-type=ALWAYS, max=3, min=0, offset=0}, i-signal-in-i-pdu=TCC_STAT_AC}
            {data-filter={data-filter-type=ALWAYS, max=3, min=0, offset=0}, i-signal-in-i-pdu=TCC_STAT_AUTO}
            {data-filter={data-filter-type=ALWAYS, max=7, min=0, offset=0}, i-signal-in-i-pdu=TCC_BlowerLevelManual}
            {data-filter={data-filter-type=ALWAYS, max=22, min=0, offset=16}, i-signal-in-i-pdu=TCC_RightZoneSetTemp}
            {data-filter={data-filter-type=ALWAYS, max=22, min=0, offset=16}, i-signal-in-i-pdu=TCC_LeftZoneSetTemp}
            {data-filter={data-filter-type=ALWAYS, max=3, min=0, offset=0}, i-signal-in-i-pdu=TCC_CoolantTempIPU_IN_error}
            {data-filter={data-filter-type=ALWAYS, max=3, min=0, offset=0}, i-signal-in-i-pdu=TCC_CabinTemp_Q}
            {data-filter={data-filter-type=ALWAYS, max=250, min=0}, i-signal-in-i-pdu=TCC_CabinTemp}
            {data-filter={data-filter-type=ALWAYS, max=255, min=0}, i-signal-in-i-pdu=TCC_AmbientTemp}
            {data-filter={data-filter-type=ALWAYS, max=250, min=0}, i-signal-in-i-pdu=TCC_AmbientTempRaw}
            {data-filter={data-filter-type=NEW-IS-WITHIN, max=65535, min=0, offset=0}, i-signal-in-i-pdu=CRC_TCC_02}
            {data-filter={data-filter-type=ALWAYS, max=255, min=0, offset=0}, i-signal-in-i-pdu=ALIVE_TCC_02}
            {data-filter={data-filter-type=ALWAYS, max=100, min=0, offset=0}, i-signal-in-i-pdu=TCC_BlowerLevel}
            {data-filter={data-filter-type=ALWAYS, max=100, min=0, offset=0}, i-signal-in-i-pdu=TCC_RSV_EDU_Position}
            {data-filter={data-filter-type=ALWAYS, max=255, min=0, offset=0}, i-signal-in-i-pdu=TCC_CoolantFlow_EDURear}
            {data-filter={data-filter-type=ALWAYS, max=255, min=0, offset=0}, i-signal-in-i-pdu=TCC_CoolantFlow_EDUFront}
            {data-filter={data-filter-type=ALWAYS, max=100, min=0, offset=0}, i-signal-in-i-pdu=TCC_WAPU_EDU}
            {data-filter={data-filter-type=ALWAYS, max=165, min=0}, i-signal-in-i-pdu=TCC_CoolantTempEDURear_IN}
            {data-filter={data-filter-type=ALWAYS, max=165, min=0}, i-signal-in-i-pdu=TCC_CoolantTempEDUFront_IN}
            {data-filter={data-filter-type=ALWAYS, max=3, min=0, offset=0}, i-signal-in-i-pdu=TCC_AmbientTemp_Q}
            {data-filter={data-filter-type=ALWAYS, max=3, min=0, offset=0}, i-signal-in-i-pdu=TCC_STAT_MaxAC}
          signal TCC_ByPassFlap_error: start 298, 2 bit, big-endian, init-value=0, base-type=uint8, compu {phys=raw for raw 0..3, 0=NOERROR, 1=ERROR, 2=RESERVED, 3=INVALID}, end-to-end-transformation-i-signal-props=data-ids=0, to Ecu_TPMS  # By Pass flap error"
          signal TCC_RecircFlap_error: start 309, 2 bit, big-endian, init-value=0, base-type=uint8, compu {phys=raw for raw 0..3, 0=NOERROR, 1=ERROR, 2=RESERVED, 3=INVALID}, end-to-end-transformation-i-signal-props=data-ids=0, to Ecu_TPMS  # Recirculation flap error"
          signal TCC_ModeFlap_error: start 311, 2 bit, big-endian, init-value=0, base-type=uint8, compu {phys=raw for raw 0..3, 0=NOERROR, 1=ERROR, 2=RESERVED, 3=INVALID}, end-to-end-transformation-i-signal-props=data-ids=0, to Ecu_TPMS  # Mode Flap error"
          signal TCC_Blower_Error: start 211, 2 bit, big-endian, init-value=0, base-type=uint8, compu {phys=raw for raw 0..3, 0=NOERROR, 1=ERROR, 2=RESERVED, 3=INVALID}, end-to-end-transformation-i-signal-props=data-ids=0, to Ecu_TPMS  # HVAC Blower error"
          signal TCC_HVAC_AirDistributionMode: start 301, 3 bit, big-endian, init-value=0, base-type=uint8, compu {phys=raw for raw 0..7, 0=VENT, 1=VENT_FOOT, 2=TRI_LEVEL_VENT_FOOT_DEFROST_, 3=FOOT, 4=WINTERBI_LEVEL, 5=DEFOG, 6=DEFROST, 7=INVALID}, end-to-end-transformation-i-signal-props=data-ids=0, to Ecu_TPMS  # HVAC flap position (air distribution mode)"
          signal TCC_HV_Compressor_Availability: start 295, 8 bit, big-endian, init-value=0, base-type=uint8, compu {phys=raw for raw 0..255, 0=NOERROR, 1=ERROR}, end-to-end-transformation-i-signal-props=data-ids=0, to Ecu_TPMS  # HV-compressor availability status"
          signal TCC_HV_Compressor_error: start 237, 2 bit, big-endian, init-value=0, base-type=uint8, compu {phys=raw for raw 0..3, 0=NOERROR, 1=ERROR, 2=RESERVED, 3=INVALID}, end-to-end-transformation-i-signal-props=data-ids=0, to Ecu_TPMS  # HV-compressor error"
          signal TCC_HV_Compressor_power: start 271, 8 bit, big-endian, init-value=0, base-type=uint8, compu {raw=phys*0.01 for phys 0..25500; unit W}, end-to-end-transformation-i-signal-props=data-ids=0, to Ecu_TPMS  # HV-compressor power"
          signal TCC_HV_PTC_HVAC_Availability: start 279, 8 bit, big-endian, init-value=0, base-type=uint8, compu {phys=raw for raw 0..255, 0=NOERROR, 1=ERROR}, end-to-end-transformation-i-signal-props=data-ids=0, to Ecu_TPMS  # HVAC PTC availability status"
          signal TCC_HV_PTC_HVAC_error: start 239, 2 bit, big-endian, init-value=0, base-type=uint8, compu {phys=raw for raw 0..3, 0=NOERROR, 1=ERROR, 2=RESERVED, 3=INVALID}, end-to-end-transformation-i-signal-props=data-ids=0, to Ecu_TPMS  # HVAC PTC error"
          signal TCC_HV_PTC_HVAC_power: start 255, 9 bit, big-endian, init-value=0, base-type=uint16, compu {raw=phys*0.01 for phys 0..12800; unit W}, end-to-end-transformation-i-signal-props=data-ids=0, to Ecu_TPMS  # HVAC PTC power total"
          signal TCC_AGM_error: start 225, 2 bit, big-endian, init-value=0, base-type=uint8, compu {phys=raw for raw 0..3, 0=NOERROR, 1=ERROR, 2=RESERVED, 3=INVALID}, end-to-end-transformation-i-signal-props=data-ids=0, to Ecu_TPMS  # Active Grill Shutter (AGS) error"
          signal TCC_EFAN_error: start 227, 2 bit, big-endian, init-value=0, base-type=uint8, compu {phys=raw for raw 0..3, 0=NOERROR, 1=ERROR, 2=RESERVED, 3=INVALID}, end-to-end-transformation-i-signal-props=data-ids=0, to Ecu_TPMS  # Cooling fan (EFAN) error"
          signal TCC_HV_PTC_Battery_Availability: start 287, 8 bit, big-endian, init-value=0, base-type=uint8, compu {phys=raw for raw 0..255, 0=NOERROR, 1=ERROR}, end-to-end-transformation-i-signal-props=data-ids=0, to Ecu_TPMS  # Battery HPTC availability status"
          signal TCC_HV_PTC_Battery_error: start 229, 2 bit, big-endian, init-value=0, base-type=uint8, compu {phys=raw for raw 0..3, 0=NOERROR, 1=ERROR, 2=RESERVED, 3=INVALID}, end-to-end-transformation-i-signal-props=data-ids=0, to Ecu_TPMS  # Battery HPTC error"
          signal TCC_HV_PTC_Battery_power: start 262, 7 bit, big-endian, init-value=0, base-type=uint8, compu {raw=phys*0.01 for phys 0..7000; unit W}, end-to-end-transformation-i-signal-props=data-ids=0, to Ecu_TPMS  # Battery HPTC power"
          signal TCC_WAPU_EDU_Error: start 231, 2 bit, big-endian, init-value=0, base-type=uint8, compu {phys=raw for raw 0..3, 0=NOERROR, 1=ERROR, 2=RESERVED, 3=INVALID}, end-to-end-transformation-i-signal-props=data-ids=0, to Ecu_TPMS  # EDU waterpump error"
          signal TCC_RSV_EDU_Error: start 217, 2 bit, big-endian, init-value=0, base-type=uint8, compu {phys=raw for raw 0..3, 0=NOERROR, 1=ERROR, 2=RESERVED, 3=INVALID}, end-to-end-transformation-i-signal-props=data-ids=0, to Ecu_TPMS  # EDU RSV error"
          signal TCC_CoolantTempEDURear_IN_error: start 219, 2 bit, big-endian, init-value=0, base-type=uint8, compu {phys=raw for raw 0..3, 0=NOERROR, 1=ERROR, 2=RESERVED, 3=INVALID}, end-to-end-transformation-i-signal-props=data-ids=0, to Ecu_TPMS  # EDU rear coolant inlet temperature sensor error"
          signal TCC_CoolantTempEDUFront_IN_error: start 221, 2 bit, big-endian, init-value=0, base-type=uint8, compu {phys=raw for raw 0..3, 0=NOERROR, 1=ERROR, 2=RESERVED, 3=INVALID}, end-to-end-transformation-i-signal-props=data-ids=0, to Ecu_TPMS  # EDU front coolant inlet temperature sensor error"
          signal TCC_EDU_Cooling_error: start 223, 2 bit, big-endian, init-value=0, base-type=uint8, compu {phys=raw for raw 0..3, 0=NOERROR, 1=ERROR, 2=RESERVED, 3=INVALID}, end-to-end-transformation-i-signal-props=data-ids=0, to Ecu_TPMS  # Error status of EDU cooling"
          signal TCC_CoolantTempIPU_IN: start 247, 8 bit, big-endian, init-value=40, base-type=uint8, compu {raw=phys+40 for phys -40..125; unit degC}, end-to-end-transformation-i-signal-props=data-ids=0, to Ecu_TPMS  # Coolant inlet temperature at IPU inlet"
          signal TCC_STAT_Defrost: start 213, 2 bit, big-endian, init-value=0, base-type=uint8, compu {phys=raw for raw 0..3, 0=NOTACTIVE, 1=ACTIVE, 2=RESERVED, 3=INVALID}, end-to-end-transformation-i-signal-props=data-ids=0, to Ecu_TPMS  # Status feedback of Defrost function"
          signal TCC_STAT_Sync: start 215, 2 bit, big-endian, init-value=0, base-type=uint8, compu {phys=raw for raw 0..3, 0=NOTACTIVE, 1=ACTIVE, 2=RESERVED, 3=INVALID}, end-to-end-transformation-i-signal-props=data-ids=0, to Ecu_TPMS  # Status feedback of SYNC function"
          signal TCC_STAT_Recirc: start 201, 2 bit, big-endian, init-value=0, base-type=uint8, compu {phys=raw for raw 0..3, 0=NOTACTIVE, 1=ACTIVE, 2=RESERVED, 3=INVALID}, end-to-end-transformation-i-signal-props=data-ids=0, to Ecu_TPMS  # Status feedback of Recirculation function"
          signal TCC_STAT_AC: start 205, 2 bit, big-endian, init-value=0, base-type=uint8, compu {phys=raw for raw 0..3, 0=NOTACTIVE, 1=ACTIVE, 2=RESERVED, 3=INVALID}, end-to-end-transformation-i-signal-props=data-ids=0, to Ecu_TPMS  # Status feedback of AC function"
          signal TCC_STAT_AUTO: start 207, 2 bit, big-endian, init-value=0, base-type=uint8, compu {phys=raw for raw 0..3, 0=NOTACTIVE, 1=ACTIVE, 2=RESERVED, 3=INVALID}, end-to-end-transformation-i-signal-props=data-ids=0, to Ecu_TPMS  # Status feedback of AUTO function"
          signal TCC_BlowerLevelManual: start 199, 3 bit, big-endian, init-value=0, base-type=uint8, compu {phys=raw for raw 0..7, 0..4=LEVEL0..LEVEL4, 5=RESERVED, 6=RESERVED, 7=INVALID}, end-to-end-transformation-i-signal-props=data-ids=0, to Ecu_TPMS  # HVAC blower level current set"
          signal TCC_RightZoneSetTemp: start 191, 5 bit, big-endian, init-value=0, base-type=uint8, compu {raw=phys*2-32 for phys 16..27; unit degC}, end-to-end-transformation-i-signal-props=data-ids=0, to Ecu_TPMS  # Right zone temperature setting for cabin conditioning"
          signal TCC_LeftZoneSetTemp: start 183, 5 bit, big-endian, init-value=0, base-type=uint8, compu {raw=phys*2-32 for phys 16..27; unit degC}, end-to-end-transformation-i-signal-props=data-ids=0, to Ecu_TPMS  # Left zone temperature setting for cabin conditioning"
          signal TCC_CoolantTempIPU_IN_error: start 331, 2 bit, big-endian, init-value=0, base-type=uint8, compu {phys=raw for raw 0..3, 0=NOERROR, 1=ERROR, 2=RESERVED, 3=INVALID}, end-to-end-transformation-i-signal-props=data-ids=0, to Ecu_TPMS  # Coolant inlet temperature at IPU inlet error"
          signal TCC_CabinTemp_Q: start 333, 2 bit, big-endian, init-value=0, base-type=uint8, compu {phys=raw for raw 0..3, 0=INIT, 1=VALID, 2=RESERVED, 3=INVALID}, end-to-end-transformation-i-signal-props=data-ids=0, to Ecu_TPMS  # Qualifier for cabin temperature sensor"
          signal TCC_CabinTemp: start 175, 8 bit, big-endian, init-value=80, base-type=uint8, compu {raw=phys*2+80 for phys -40..85; unit degC}, end-to-end-transformation-i-signal-props=data-ids=0, to Ecu_TPMS  # Cabin temperature inside the vehicle"
          signal TCC_AmbientTemp: start 167, 8 bit, big-endian, init-value=80, base-type=uint8, compu {raw=phys*2+80 for phys -40..87.5; unit degC}, end-to-end-transformation-i-signal-props=data-ids=0, to Ecu_TPMS  # Ambient temperature outside the vehicle"
          signal TCC_AmbientTempRaw: start 159, 8 bit, big-endian, init-value=40, base-type=uint8, compu {raw=phys+40 for phys -40..210; unit degC}, end-to-end-transformation-i-signal-props=data-ids=0, to Ecu_TPMS  # Ambient Temperature Raw"
          signal CRC_TCC_02: start 7, 16 bit, big-endian, init-value=0, base-type=uint16, compu {raw=phys for phys 0..65535}, end-to-end-transformation-i-signal-props=data-ids=0, to Ecu_TPMS  # DataID=0x0058. Checksum calculation accordig CAN Specification. Cyclic Redundancy Check"
          signal ALIVE_TCC_02: start 23, 8 bit, big-endian, init-value=0, base-type=uint8, compu {raw=phys for phys 0..255}, end-to-end-transformation-i-signal-props=data-ids=0, to Ecu_TPMS  # Alive Counter"
          signal TCC_BlowerLevel: start 135, 7 bit, big-endian, init-value=0, base-type=uint8, compu {phys=raw for raw 0..100, 127=INVALID; unit pct}, end-to-end-transformation-i-signal-props=data-ids=0, to Ecu_TPMS
          signal TCC_RSV_EDU_Position: start 151, 7 bit, big-endian, init-value=0, base-type=uint8, compu {raw=phys for phys 0..100; unit pct}, end-to-end-transformation-i-signal-props=data-ids=0, to Ecu_TPMS  # EDU RSV position "
          signal TCC_CoolantFlow_EDURear: start 127, 8 bit, big-endian, init-value=0, base-type=uint8, compu {raw=phys*2 for phys 0..127.5; unit l_min}, end-to-end-transformation-i-signal-props=data-ids=0, to Ecu_TPMS  # EDU rear coolant volume flow"
          signal TCC_CoolantFlow_EDUFront: start 119, 8 bit, big-endian, init-value=0, base-type=uint8, compu {raw=phys*2 for phys 0..127.5; unit l_min}, end-to-end-transformation-i-signal-props=data-ids=0, to Ecu_TPMS  # EDU front coolant volume flow"
          signal TCC_WAPU_EDU: start 143, 7 bit, big-endian, init-value=0, base-type=uint8, compu {raw=phys for phys 0..100; unit pct}, end-to-end-transformation-i-signal-props=data-ids=0, to Ecu_TPMS  # EDU waterpump speed"
          signal TCC_CoolantTempEDURear_IN: start 111, 8 bit, big-endian, init-value=40, base-type=uint8, compu {raw=phys+40 for phys -40..125; unit degC}, end-to-end-transformation-i-signal-props=data-ids=0, to Ecu_TPMS  # EDU rear coolant inlet temperature"
          signal TCC_CoolantTempEDUFront_IN: start 103, 8 bit, big-endian, init-value=40, base-type=uint8, compu {raw=phys+40 for phys -40..125; unit degC}, end-to-end-transformation-i-signal-props=data-ids=0, to Ecu_TPMS  # EDU front coolant inlet temperature"
          signal TCC_AmbientTemp_Q: start 335, 2 bit, big-endian, init-value=0, base-type=uint8, compu {phys=raw for raw 0..3, 0=INIT, 1=VALID, 2=RESERVED, 3=INVALID}, end-to-end-transformation-i-signal-props=data-ids=0, to Ecu_TPMS  # Qualifier for ambient temperature sensor "
          signal TCC_STAT_MaxAC: start 203, 2 bit, big-endian, init-value=0, base-type=uint8, compu {phys=raw for raw 0..3, 0=NOTACTIVE, 1=ACTIVE, 2=RESERVED, 3=INVALID}, end-to-end-transformation-i-signal-props=data-ids=0, to Ecu_TPMS  # Status feedback of MAX AC function"
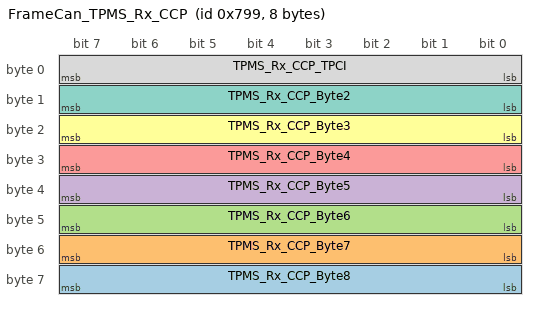
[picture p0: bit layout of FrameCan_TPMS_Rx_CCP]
      frame FrameCan_TPMS_Rx_CCP: id 0x799, to Ecu_TPMS, frame-length=8, can-addressing-mode=STANDARD
        carries pdu IPduISignal_TPMS_Rx_CCP: packing-byte-order=big-endian, start-position=7
        pdu IPduISignal_TPMS_Rx_CCP: length=8
          transmission-mode-conditions:
            {data-filter={data-filter-type=ALWAYS, max=255, min=0, offset=0}, i-signal-in-i-pdu=TPMS_Rx_CCP_Byte8}
            {data-filter={data-filter-type=ALWAYS, max=255, min=0, offset=0}, i-signal-in-i-pdu=TPMS_Rx_CCP_Byte7}
            {data-filter={data-filter-type=ALWAYS, max=255, min=0, offset=0}, i-signal-in-i-pdu=TPMS_Rx_CCP_Byte6}
            {data-filter={data-filter-type=ALWAYS, max=255, min=0, offset=0}, i-signal-in-i-pdu=TPMS_Rx_CCP_Byte5}
            {data-filter={data-filter-type=ALWAYS, max=255, min=0, offset=0}, i-signal-in-i-pdu=TPMS_Rx_CCP_Byte4}
            {data-filter={data-filter-type=ALWAYS, max=255, min=0, offset=0}, i-signal-in-i-pdu=TPMS_Rx_CCP_Byte3}
            {data-filter={data-filter-type=ALWAYS, max=255, min=0, offset=0}, i-signal-in-i-pdu=TPMS_Rx_CCP_Byte2}
            {data-filter={data-filter-type=ALWAYS, max=255, min=0, offset=0}, i-signal-in-i-pdu=TPMS_Rx_CCP_TPCI}
          signal TPMS_Rx_CCP_Byte8: start 63, 8 bit, big-endian, init-value=0, base-type=uint8, compu {raw=phys for phys 0..255}, end-to-end-transformation-i-signal-props=data-ids=0, to Ecu_TPMS  # CCP signal"
          signal TPMS_Rx_CCP_Byte7: start 55, 8 bit, big-endian, init-value=0, base-type=uint8, compu {raw=phys for phys 0..255}, end-to-end-transformation-i-signal-props=data-ids=0, to Ecu_TPMS  # CCP signal"
          signal TPMS_Rx_CCP_Byte6: start 47, 8 bit, big-endian, init-value=0, base-type=uint8, compu {raw=phys for phys 0..255}, end-to-end-transformation-i-signal-props=data-ids=0, to Ecu_TPMS  # CCP signal"
          signal TPMS_Rx_CCP_Byte5: start 39, 8 bit, big-endian, init-value=0, base-type=uint8, compu {raw=phys for phys 0..255}, end-to-end-transformation-i-signal-props=data-ids=0, to Ecu_TPMS  # CCP signal"
          signal TPMS_Rx_CCP_Byte4: start 31, 8 bit, big-endian, init-value=0, base-type=uint8, compu {raw=phys for phys 0..255}, end-to-end-transformation-i-signal-props=data-ids=0, to Ecu_TPMS  # CCP signal"
          signal TPMS_Rx_CCP_Byte3: start 23, 8 bit, big-endian, init-value=0, base-type=uint8, compu {raw=phys for phys 0..255}, end-to-end-transformation-i-signal-props=data-ids=0, to Ecu_TPMS  # CCP signal"
          signal TPMS_Rx_CCP_Byte2: start 15, 8 bit, big-endian, init-value=0, base-type=uint8, compu {raw=phys for phys 0..255}, end-to-end-transformation-i-signal-props=data-ids=0, to Ecu_TPMS  # CCP signal"
          signal TPMS_Rx_CCP_TPCI: start 7, 8 bit, big-endian, init-value=0, base-type=uint8, compu {raw=phys for phys 0..255}, end-to-end-transformation-i-signal-props=data-ids=0, to Ecu_TPMS  # CCP signal"
      frame FrameCan_VCU_05: id 0x110, to Ecu_TPMS, frame-length=20, can-addressing-mode=STANDARD, can-fd-frame-support=false, can-frame-rx-behavior=CAN-FD
        carries pdu IPduISignal_VCU_05: packing-byte-order=big-endian, start-position=7
        pdu IPduISignal_VCU_05: length=20, transmission-mode-false-timing=cyclic-timing={time-offset=0.0, time-period=0.01}, transmission-mode-true-timing=cyclic-timing={time-offset=0.0, time-period=0.01}
          transmission-mode-conditions:
            {data-filter={data-filter-type=ALWAYS, max=0, min=0, offset=0}, i-signal-in-i-pdu=VCU_AccelPedalSts}
            {data-filter={data-filter-type=NEW-IS-WITHIN, max=18446744073709551615, min=0, offset=0}, i-signal-in-i-pdu=SSecOC_MAC_VCU_05}
            {data-filter={data-filter-type=ALWAYS, max=255, min=0, offset=0}, i-signal-in-i-pdu=SSecOC_Fresh_VCU_05}
            {data-filter={data-filter-type=ALWAYS, max=7, min=0, offset=0}, i-signal-in-i-pdu=VCU_CC_SpdLim_Sts}
            {data-filter={data-filter-type=ALWAYS, max=255, min=0, offset=0}, i-signal-in-i-pdu=ALIVE_VCU_05}
            {data-filter={data-filter-type=NEW-IS-WITHIN, max=65535, min=0, offset=0}, i-signal-in-i-pdu=CRC_VCU_05}
            {data-filter={data-filter-type=ALWAYS, max=15, min=0, offset=0}, i-signal-in-i-pdu=VCU_ActSt}
            {data-filter={data-filter-type=ALWAYS, max=15, min=0, offset=0}, i-signal-in-i-pdu=VCU_GearSig}
            {data-filter={data-filter-type=ALWAYS, max=3, min=0, offset=0}, i-signal-in-i-pdu=VCU_GearSig_Q}
          signal VCU_AccelPedalSts: start 97, 2 bit, big-endian, init-value=0, base-type=uint8, compu {phys=raw for raw 0, 0=NOTPRESSED, 1=PRESSED, 2=UNAVAIABLE, 3=FAULT}, end-to-end-transformation-i-signal-props=data-ids=0, to Ecu_TPMS  # Accelerator Pedal Status"
          signal SSecOC_MAC_VCU_05: start 39, 64 bit, big-endian, init-value=0, base-type=uint64, compu {raw=phys for phys 0..1.84467440737096E19}, end-to-end-transformation-i-signal-props=data-ids=0, to Ecu_TPMS  # Short SecOC MAC signal byte 0 on CAN"
          signal SSecOC_Fresh_VCU_05: start 31, 8 bit, big-endian, init-value=0, base-type=uint8, compu {raw=phys for phys 0..255}, end-to-end-transformation-i-signal-props=data-ids=0, to Ecu_TPMS  # Short SecOC Fresh signal byte 0 on CAN"
          signal VCU_CC_SpdLim_Sts: start 107, 3 bit, big-endian, init-value=0, base-type=uint8, compu {phys=raw for raw 0..7, 0=INIT, 1=NOTACTIVE, 2=CCACTIVE, 3=LIMACTIVE, 4=ERROR, 5=RESERVED_CCSTANDBY, 6=RESERVED_SPEEDLIMSTANDBY, 7=INVALID}, end-to-end-transformation-i-signal-props=data-ids=0, to Ecu_TPMS  # Cruise Control and Speed limiter "
          signal ALIVE_VCU_05: start 23, 8 bit, big-endian, init-value=0, base-type=uint8, compu {raw=phys for phys 0..255}, end-to-end-transformation-i-signal-props=data-ids=0, to Ecu_TPMS  # Alive Counter"
          signal CRC_VCU_05: start 7, 16 bit, big-endian, init-value=0, base-type=uint16, compu {raw=phys for phys 0..65535}, end-to-end-transformation-i-signal-props=data-ids=0, to Ecu_TPMS  # DataID=0x0060. Checksum calculation accordig CAN Specification. Cyclic Redundancy Check"
          signal VCU_ActSt: start 111, 4 bit, big-endian, init-value=0, base-type=uint8, compu {phys=raw for raw 0..15, 0=SLEEP, 1=INIT, 2=ACTIVE, 3=PREPARESHUTDOWN, 4=SHUTDOWN, 5..8=RESERVED}, end-to-end-transformation-i-signal-props=data-ids=0, to Ecu_TPMS  # VCU Actual Status"
          signal VCU_GearSig: start 103, 4 bit, big-endian, init-value=0, base-type=uint8, compu {phys=raw for raw 0..15, 11..15=RESERVED, 0=UNDEFINED_INITIAL_VALUE, 1=GEAR_P, 2=GEAR_N, 3=GEAR_R, 4=GREAR_D, 5=ENGAGE_P, 6=RESERVED, 7=RESERVED, 8=FAULT, 9=RESERVED, 10=RESERVED}, end-to-end-transformation-i-signal-props=data-ids=0, to Ecu_TPMS  # Gear signal"
          signal VCU_GearSig_Q: start 99, 2 bit, big-endian, init-value=0, base-type=uint8, compu {phys=raw for raw 0..3, 0=INITIALIZING, 1=VALID, 2=INVALID, 3=RESERVED}, end-to-end-transformation-i-signal-props=data-ids=0, to Ecu_TPMS  # Effective bit of gear signal"
      frame FrameCan_Diag_ResPhys_TPMS: id 0x18DAF119, from Ecu_TPMS, frame-length=64, can-addressing-mode=EXTENDED, can-fd-frame-support=false, can-frame-tx-behavior=CAN-FD
        carries pdu IPduDcm_Diag_ResPhys_TPMS: packing-byte-order=big-endian, start-position=7
        dcm i pdu IPduDcm_Diag_ResPhys_TPMS: length=64, diag-pdu-type=DIAG-RESPONSE
      frame FrameCan_Meas_TPMS_1: id 0x779, from Ecu_TPMS, frame-length=8, can-addressing-mode=STANDARD, can-frame-tx-behavior=CAN-20
        carries pdu IPduMultiplexed_Meas_TPMS_1_IPDU: packing-byte-order=big-endian, start-position=7
        multiplexed i pdu IPduMultiplexed_Meas_TPMS_1_IPDU:
          length=8
          dynamic-part{segment-positions=[{segment-byte-order=big-endian, segment-length=8, segment-position=55}, {segment-byte-order=big-endian, segment-length=8, segment-position=39}, {segment-byte-order=big-endian, segment-length=8, segment-position=23}, {segment-byte-order=big-endian, segment-length=8, segment-position=7}, {segment-byte-order=big-endian, segment-length=8, segment-position=63}, {segment-byte-order=big-endian, segment-length=8, segment-position=31}, {segment-byte-order=big-endian, segment-length=8, segment-position=15}], dynamic-part-alternatives=[{i-pdu=IPduISignal_Meas_TPMS_1_MUX1, initial-dynamic-part=true, selector-field-code=1}, {i-pdu=IPduISignal_Meas_TPMS_1_MUX2, initial-dynamic-part=false, selector-field-code=2}]}
          selector-field-byte-order=big-endian
          selector-field-length=8
          selector-field-start-position=7
          static-part{segment-position{segment-byte-order=big-endian, segment-length=8, segment-position=47}, i-pdu=IPduISignal_Meas_TPMS_1_MUX_STAT}
          trigger-mode=STATIC-OR-DYNAMIC-PART-TRIGGER
      frame FrameCan_NM_TPMS: id 0x519, from Ecu_TPMS, frame-length=8, can-addressing-mode=STANDARD, can-frame-tx-behavior=CAN-20  # Networkmanagement message"
        carries pdu IPduISignal_NM_TPMS: packing-byte-order=big-endian, start-position=7
        pdu IPduISignal_NM_TPMS: length=8, transmission-mode-false-timing=event-controlled-timing=number-of-repetitions=0, transmission-mode-true-timing=event-controlled-timing=number-of-repetitions=0  # Networkmanagement message
          transmission-mode-conditions:
            {data-filter={data-filter-type=ALWAYS, max=1, min=0, offset=0}, i-signal-in-i-pdu=usrData1_TPM_Bit7_ECUSPEC_AWAKE}
            {data-filter={data-filter-type=ALWAYS, max=1, min=0, offset=0}, i-signal-in-i-pdu=usrData1_TPM_Bit6_DIAGN_AWAKE}
            {data-filter={data-filter-type=ALWAYS, max=1, min=0, offset=0}, i-signal-in-i-pdu=usrData1_TPM_Bit5_IGNITION_AWAKE}
            {data-filter={data-filter-type=ALWAYS, max=1, min=0, offset=0}, i-signal-in-i-pdu=usrData1_TPM_Bit4_NETWORK_AWAKE}
            {data-filter={data-filter-type=ALWAYS, max=1, min=0, offset=0}, i-signal-in-i-pdu=usrData1_TPM_Bit3_ECUSPEC_WAKEUP}
            {data-filter={data-filter-type=ALWAYS, max=1, min=0, offset=0}, i-signal-in-i-pdu=usrData1_TPM_Bit2_NETWORK_WAKEUP}
            {data-filter={data-filter-type=ALWAYS, max=1, min=0, offset=0}, i-signal-in-i-pdu=usrData1_TPM_Bit1_RESET_WAKEUP}
            {data-filter={data-filter-type=ALWAYS, max=1, min=0, offset=0}, i-signal-in-i-pdu=CtrlBitVector_TPM_Bit7_Res}
            {data-filter={data-filter-type=ALWAYS, max=1, min=0, offset=0}, i-signal-in-i-pdu=CtrlBitVector_TPM_Bit6_PNI}
            {data-filter={data-filter-type=ALWAYS, max=1, min=0, offset=0}, i-signal-in-i-pdu=CtrlBitVector_TPM_Bit5_Res}
            {data-filter={data-filter-type=ALWAYS, max=1, min=0, offset=0}, i-signal-in-i-pdu=CtrlBitVector_TPM_Bit4_ActWake}
            {data-filter={data-filter-type=ALWAYS, max=1, min=0, offset=0}, i-signal-in-i-pdu=CtrlBitVector_TPM_Bit3_NMCoord}
            {data-filter={data-filter-type=ALWAYS, max=1, min=0, offset=0}, i-signal-in-i-pdu=CtrlBitVector_TPM_Bit2_Res}
            {data-filter={data-filter-type=ALWAYS, max=1, min=0, offset=0}, i-signal-in-i-pdu=CtrlBitVector_TPM_Bit1_Res}
            {data-filter={data-filter-type=ALWAYS, max=1, min=0, offset=0}, i-signal-in-i-pdu=usrData1_TPM_Bit0_IGN_WAKEUP}
            {data-filter={data-filter-type=ALWAYS, max=255, min=0, offset=0}, i-signal-in-i-pdu=usrData0_TPM}
            {data-filter={data-filter-type=ALWAYS, max=127, min=0, offset=0}, i-signal-in-i-pdu=srcNodeID_TPM}
            {data-filter={data-filter-type=ALWAYS, max=1, min=0, offset=0}, i-signal-in-i-pdu=CtrlBitVector_TPM_Bit0_RMR}
            {data-filter={data-filter-type=ALWAYS, max=255, min=0, offset=0}, i-signal-in-i-pdu=usrData2_TPM}
            {data-filter={data-filter-type=ALWAYS, max=255, min=0, offset=0}, i-signal-in-i-pdu=usrData4_TPM_PN_Info1}
            {data-filter={data-filter-type=ALWAYS, max=255, min=0, offset=0}, i-signal-in-i-pdu=usrData5_TPM_PN_Info2}
            {data-filter={data-filter-type=ALWAYS, max=255, min=0, offset=0}, i-signal-in-i-pdu=usrData3_TPM}
          signal usrData1_TPM_Bit7_ECUSPEC_AWAKE: start 31, 1 bit, big-endian, init-value=0, base-type=uint8, compu {phys=raw for raw 0..1, 0=INACTIVE, 1=ACTIVE}, end-to-end-transformation-i-signal-props=data-ids=0
          signal usrData1_TPM_Bit6_DIAGN_AWAKE: start 30, 1 bit, big-endian, init-value=0, base-type=uint8, compu {phys=raw for raw 0..1, 0=INACTIVE, 1=ACTIVE}, end-to-end-transformation-i-signal-props=data-ids=0
          signal usrData1_TPM_Bit5_IGNITION_AWAKE: start 29, 1 bit, big-endian, init-value=0, base-type=uint8, compu {phys=raw for raw 0..1, 0=INACTIVE, 1=ACTIVE}, end-to-end-transformation-i-signal-props=data-ids=0
          signal usrData1_TPM_Bit4_NETWORK_AWAKE: start 28, 1 bit, big-endian, init-value=0, base-type=uint8, compu {phys=raw for raw 0..1, 0=INACTIVE, 1=ACTIVE}, end-to-end-transformation-i-signal-props=data-ids=0
          signal usrData1_TPM_Bit3_ECUSPEC_WAKEUP: start 27, 1 bit, big-endian, init-value=0, base-type=uint8, compu {phys=raw for raw 0..1, 0=INACTIVE, 1=ACTIVE}, end-to-end-transformation-i-signal-props=data-ids=0
          signal usrData1_TPM_Bit2_NETWORK_WAKEUP: start 26, 1 bit, big-endian, init-value=0, base-type=uint8, compu {phys=raw for raw 0..1, 0=INACTIVE, 1=ACTIVE}, end-to-end-transformation-i-signal-props=data-ids=0
          signal usrData1_TPM_Bit1_RESET_WAKEUP: start 25, 1 bit, big-endian, init-value=0, base-type=uint8, compu {phys=raw for raw 0..1, 0=INACTIVE, 1=ACTIVE}, end-to-end-transformation-i-signal-props=data-ids=0
          signal CtrlBitVector_TPM_Bit7_Res: start 15, 1 bit, big-endian, init-value=0, base-type=uint8, compu {raw=phys for phys 0..1}, end-to-end-transformation-i-signal-props=data-ids=0
          signal CtrlBitVector_TPM_Bit6_PNI: start 14, 1 bit, big-endian, init-value=0, base-type=uint8, compu {raw=phys for phys 0..1}, end-to-end-transformation-i-signal-props=data-ids=0
          signal CtrlBitVector_TPM_Bit5_Res: start 13, 1 bit, big-endian, init-value=0, base-type=uint8, compu {raw=phys for phys 0..1}, end-to-end-transformation-i-signal-props=data-ids=0
          signal CtrlBitVector_TPM_Bit4_ActWake: start 12, 1 bit, big-endian, init-value=0, base-type=uint8, compu {raw=phys for phys 0..1}, end-to-end-transformation-i-signal-props=data-ids=0
          signal CtrlBitVector_TPM_Bit3_NMCoord: start 11, 1 bit, big-endian, init-value=0, base-type=uint8, compu {phys=raw for raw 0..1, 0=STARTOFSYNCHRONIZEDSHUTDOWNISNOTREQUESTEDBYMAINCOORDINATOR, 1=STARTOFSYNCHRONIZEDSHUTDOWNISREQUESTEDBYMAINCOORDINATOR}, end-to-end-transformation-i-signal-props=data-ids=0
          signal CtrlBitVector_TPM_Bit2_Res: start 10, 1 bit, big-endian, init-value=0, base-type=uint8, compu {raw=phys for phys 0..1}, end-to-end-transformation-i-signal-props=data-ids=0
          signal CtrlBitVector_TPM_Bit1_Res: start 9, 1 bit, big-endian, init-value=0, base-type=uint8, compu {raw=phys for phys 0..1}, end-to-end-transformation-i-signal-props=data-ids=0
          signal usrData1_TPM_Bit0_IGN_WAKEUP: start 24, 1 bit, big-endian, init-value=0, base-type=uint8, compu {phys=raw for raw 0..1, 0=INACTIVE, 1=ACTIVE}, end-to-end-transformation-i-signal-props=data-ids=0
          signal usrData0_TPM: start 23, 8 bit, big-endian, init-value=0, base-type=uint8, compu {phys=raw for raw 0..255, 0=USERDATAFORCURRENTVEHICLEWITHOUTPARTIALNETWORKING, 1=USERDATAFORCURRENTVEHICLEWITHPARTIALNETWORKING, 255=USERDATANOTUSED}, end-to-end-transformation-i-signal-props=data-ids=0
          signal srcNodeID_TPM: start 7, 8 bit, big-endian, init-value=0, base-type=uint8, compu {raw=phys for phys 0..127}, end-to-end-transformation-i-signal-props=data-ids=0
          signal CtrlBitVector_TPM_Bit0_RMR: start 8, 1 bit, big-endian, init-value=0, base-type=uint8, compu {raw=phys for phys 0..1}, end-to-end-transformation-i-signal-props=data-ids=0
          signal usrData2_TPM: start 39, 8 bit, big-endian, init-value=0, base-type=uint8, compu {raw=phys for phys 0..255}, end-to-end-transformation-i-signal-props=data-ids=0
          signal usrData4_TPM_PN_Info1: start 55, 8 bit, big-endian, init-value=0, base-type=uint8, compu {raw=phys for phys 0..255}, end-to-end-transformation-i-signal-props=data-ids=0
          signal usrData5_TPM_PN_Info2: start 63, 8 bit, big-endian, init-value=0, base-type=uint8, compu {raw=phys for phys 0..255}, end-to-end-transformation-i-signal-props=data-ids=0
          signal usrData3_TPM: start 47, 8 bit, big-endian, init-value=0, base-type=uint8, compu {raw=phys for phys 0..255}, end-to-end-transformation-i-signal-props=data-ids=0
      frame FrameCan_TPMS_01: id 0x210, from Ecu_TPMS, frame-length=32, can-addressing-mode=STANDARD, can-fd-frame-support=false, can-frame-tx-behavior=CAN-FD
        carries pdu IPduISignal_TPMS_01: packing-byte-order=big-endian, start-position=7
        pdu IPduISignal_TPMS_01: length=32, transmission-mode-false-timing=cyclic-timing={time-offset=0.0, time-period=1.0}, transmission-mode-true-timing=cyclic-timing={time-offset=0.0, time-period=1.0}
          transmission-mode-conditions:
            {data-filter={data-filter-type=ALWAYS, max=1, min=0, offset=0}, i-signal-in-i-pdu=TPM_MalfLmp_On_Rq}
            {data-filter={data-filter-type=ALWAYS, max=1, min=0, offset=0}, i-signal-in-i-pdu=TPM_IndLmp_On_Rq}
            {data-filter={data-filter-type=ALWAYS, max=7, min=0, offset=0}, i-signal-in-i-pdu=TPM_WarnDisp_Rq}
            {data-filter={data-filter-type=ALWAYS, max=7, min=0, offset=0}, i-signal-in-i-pdu=TPM_Stat}
            {data-filter={data-filter-type=ALWAYS, max=15, min=0, offset=0}, i-signal-in-i-pdu=TPM_MsgDisp_Rq}
            {data-filter={data-filter-type=ALWAYS, max=1, min=0, offset=0}, i-signal-in-i-pdu=Press_Disp_Avl}
            {data-filter={data-filter-type=ALWAYS, max=3, min=0, offset=0}, i-signal-in-i-pdu=TireStat_FR}
            {data-filter={data-filter-type=ALWAYS, max=3, min=0, offset=0}, i-signal-in-i-pdu=TireStat_RL}
            {data-filter={data-filter-type=ALWAYS, max=3, min=0, offset=0}, i-signal-in-i-pdu=TireStat_RR}
            {data-filter={data-filter-type=ALWAYS, max=3, min=0, offset=0}, i-signal-in-i-pdu=TireStat_FL}
            {data-filter={data-filter-type=ALWAYS, max=253, min=0, offset=0}, i-signal-in-i-pdu=TirePress_RR}
            {data-filter={data-filter-type=ALWAYS, max=253, min=0, offset=0}, i-signal-in-i-pdu=TirePress_RL}
            {data-filter={data-filter-type=ALWAYS, max=253, min=0, offset=0}, i-signal-in-i-pdu=TirePress_FR}
            {data-filter={data-filter-type=ALWAYS, max=253, min=0, offset=0}, i-signal-in-i-pdu=TirePress_FL}
            {data-filter={data-filter-type=ALWAYS, max=7, min=0, offset=0}, i-signal-in-i-pdu=Tire_Temp_WarnDisp_Rq}
            {data-filter={data-filter-type=ALWAYS, max=3, min=0, offset=0}, i-signal-in-i-pdu=Tire_Temp_Stat_RR}
            {data-filter={data-filter-type=ALWAYS, max=3, min=0, offset=0}, i-signal-in-i-pdu=Tire_Temp_Stat_RL}
            {data-filter={data-filter-type=ALWAYS, max=3, min=0, offset=0}, i-signal-in-i-pdu=Tire_Temp_Stat_FR}
            {data-filter={data-filter-type=ALWAYS, max=3, min=0, offset=0}, i-signal-in-i-pdu=Tire_Temp_Stat_FL}
            {data-filter={data-filter-type=ALWAYS, max=253, min=0, offset=0}, i-signal-in-i-pdu=RefPress_Rear}
            {data-filter={data-filter-type=ALWAYS, max=253, min=0, offset=0}, i-signal-in-i-pdu=RefPress_Front}
            {data-filter={data-filter-type=ALWAYS, max=254, min=0}, i-signal-in-i-pdu=TireTemp_RR}
            {data-filter={data-filter-type=ALWAYS, max=254, min=0}, i-signal-in-i-pdu=TireTemp_RL}
            {data-filter={data-filter-type=ALWAYS, max=254, min=0}, i-signal-in-i-pdu=TireTemp_FR}
            {data-filter={data-filter-type=ALWAYS, max=254, min=0}, i-signal-in-i-pdu=TireTemp_FL}
            {data-filter={data-filter-type=ALWAYS, max=255, min=0, offset=0}, i-signal-in-i-pdu=ALIVE_TPMS_01}
            {data-filter={data-filter-type=NEW-IS-WITHIN, max=65535, min=0, offset=0}, i-signal-in-i-pdu=CRC_TPMS_01}
          signal TPM_MalfLmp_On_Rq: start 211, 1 bit, big-endian, init-value=0, base-type=uint8, compu {phys=raw for raw 0..1, 0=OFF, 1=ON}, end-to-end-transformation-i-signal-props=data-ids=0  # Request Tire Pressure Monitoring Malfunction Lamp"
          signal TPM_IndLmp_On_Rq: start 212, 1 bit, big-endian, init-value=0, base-type=uint8, compu {phys=raw for raw 0..1, 0=OFF, 1=ON}, end-to-end-transformation-i-signal-props=data-ids=0  # Request Tire Pressure Monitoring Indication Lamp"
          signal TPM_WarnDisp_Rq: start 215, 3 bit, big-endian, init-value=0, base-type=uint8, compu {phys=raw for raw 0..7, 0=NO_WARN, 1=SOFT, 2=LOW_P, 3=FAST, 7=SNA}, end-to-end-transformation-i-signal-props=data-ids=0  # Request Tire Pressure Monitioring Warning Display"
          signal TPM_Stat: start 202, 3 bit, big-endian, init-value=0, base-type=uint8, compu {phys=raw for raw 0..7, 0=ACTIVE, 1=WAIT, 2=ERROR, 3=NO_SENSORS, 7=SNA}, end-to-end-transformation-i-signal-props=data-ids=0  # Status Tire Pressure Monitoring"
          signal TPM_MsgDisp_Rq: start 206, 4 bit, big-endian, init-value=0, base-type=uint8, compu {phys=raw for raw 0..15, 0=NO_MESSAGE, 1=UNPLAUSIBLE, 2=NO_SENSORS, 3=ERROR, 15=SNA, 4=TNA, 5=WE_MISS, 6=RESTART}, end-to-end-transformation-i-signal-props=data-ids=0  # Request tire pressure monitoring display"
          signal Press_Disp_Avl: start 207, 1 bit, big-endian, init-value=0, base-type=uint8, compu {phys=raw for raw 0..1, 0=NOT_AVAILABLE, 1=AVAILABLE}, end-to-end-transformation-i-signal-props=data-ids=0  # Pressure display avaiable"
          signal TireStat_FR: start 197, 2 bit, big-endian, init-value=0, base-type=uint8, compu {phys=raw for raw 0..3, 0=NORMAL, 1=SOFT_WARNING, 2=LOW_PRESSURE, 3=FAST_DEFLATION}, end-to-end-transformation-i-signal-props=data-ids=0  # Tire status front right"
          signal TireStat_RL: start 195, 2 bit, big-endian, init-value=0, base-type=uint8, compu {phys=raw for raw 0..3, 0=NORMAL, 1=SOFT_WARNING, 2=LOW_PRESSURE, 3=FAST_DEFLATION}, end-to-end-transformation-i-signal-props=data-ids=0  # Tire status rear left"
          signal TireStat_RR: start 193, 2 bit, big-endian, init-value=0, base-type=uint8, compu {phys=raw for raw 0..3, 0=NORMAL, 1=SOFT_WARNING, 2=LOW_PRESSURE, 3=FAST_DEFLATION}, end-to-end-transformation-i-signal-props=data-ids=0  # Tire status rear right"
          signal TireStat_FL: start 199, 2 bit, big-endian, init-value=0, base-type=uint8, compu {phys=raw for raw 0..3, 0=NORMAL, 1=SOFT_WARNING, 2=LOW_PRESSURE, 3=FAST_DEFLATION}, end-to-end-transformation-i-signal-props=data-ids=0  # Tire status front left"
          signal TirePress_RR: start 191, 8 bit, big-endian, init-value=0, base-type=uint8, compu {phys=raw*2.5 for raw 0..253, 254=NO_IND, 255=SNA; unit kPa}, end-to-end-transformation-i-signal-props=data-ids=0  # Tire pressure rear right"
          signal TirePress_RL: start 183, 8 bit, big-endian, init-value=0, base-type=uint8, compu {phys=raw*2.5 for raw 0..253, 254=NO_IND, 255=SNA; unit kPa}, end-to-end-transformation-i-signal-props=data-ids=0  # Tire pressure rear left"
          signal TirePress_FR: start 175, 8 bit, big-endian, init-value=0, base-type=uint8, compu {phys=raw*2.5 for raw 0..253, 254=NO_IND, 255=SNA; unit kPa}, end-to-end-transformation-i-signal-props=data-ids=0  # Tire pressure front right"
          signal TirePress_FL: start 167, 8 bit, big-endian, init-value=0, base-type=uint8, compu {phys=raw*2.5 for raw 0..253, 254=NO_IND, 255=SNA; unit kPa}, end-to-end-transformation-i-signal-props=data-ids=0  # Tire pressure front left"
          signal Tire_Temp_WarnDisp_Rq: start 159, 3 bit, big-endian, init-value=0, base-type=uint8, compu {phys=raw for raw 0..7, 0=NO_MESSAGE, 1=TIRE_OVERHEATED, 2=REDUCE_SPEED, 7=SNA}, end-to-end-transformation-i-signal-props=data-ids=0  # Request display warning tire temperature"
          signal Tire_Temp_Stat_RR: start 145, 2 bit, big-endian, init-value=0, base-type=uint8, compu {phys=raw for raw 0..3, 0=NORMAL, 1=WARM, 2=HOT, 3=SNA}, end-to-end-transformation-i-signal-props=data-ids=0  # Status Tire Temperature Rear Right"
          signal Tire_Temp_Stat_RL: start 147, 2 bit, big-endian, init-value=0, base-type=uint8, compu {phys=raw for raw 0..3, 0=NORMAL, 1=WARM, 2=HOT, 3=SNA}, end-to-end-transformation-i-signal-props=data-ids=0  # Status Tire Temperature Rear Left"
          signal Tire_Temp_Stat_FR: start 149, 2 bit, big-endian, init-value=0, base-type=uint8, compu {phys=raw for raw 0..3, 0=NORMAL, 1=WARM, 2=HOT, 3=SNA}, end-to-end-transformation-i-signal-props=data-ids=0  # Status Tire Temperature Front Right"
          signal Tire_Temp_Stat_FL: start 151, 2 bit, big-endian, init-value=0, base-type=uint8, compu {phys=raw for raw 0..3, 0=NORMAL, 1=WARM, 2=HOT, 3=SNA}, end-to-end-transformation-i-signal-props=data-ids=0  # Status Tire Temperature front left"
          signal RefPress_Rear: start 143, 8 bit, big-endian, init-value=0, base-type=uint8, compu {phys=raw*2.5 for raw 0..253, 254=NO_IND, 255=SNA; unit kPa}, end-to-end-transformation-i-signal-props=data-ids=0  # Reference Pressure rear"
          signal RefPress_Front: start 135, 8 bit, big-endian, init-value=0, base-type=uint8, compu {phys=raw*2.5 for raw 0..253, 254=NO_IND, 255=SNA; unit kPa}, end-to-end-transformation-i-signal-props=data-ids=0  # Reference Pressure front"
          signal TireTemp_RR: start 127, 8 bit, big-endian, init-value=0, base-type=uint8, compu {phys=raw-50 for raw 0..254, 255=SNA; unit degC}, end-to-end-transformation-i-signal-props=data-ids=0  # Tire Temperature Rear Right"
          signal TireTemp_RL: start 119, 8 bit, big-endian, init-value=0, base-type=uint8, compu {phys=raw-50 for raw 0..254, 255=SNA; unit degC}, end-to-end-transformation-i-signal-props=data-ids=0  # Tire Temperature Rear Left"
          signal TireTemp_FR: start 111, 8 bit, big-endian, init-value=0, base-type=uint8, compu {phys=raw-50 for raw 0..254, 255=SNA; unit degC}, end-to-end-transformation-i-signal-props=data-ids=0  # Tire Temperature Front Right"
          signal TireTemp_FL: start 103, 8 bit, big-endian, init-value=0, base-type=uint8, compu {phys=raw-50 for raw 0..254, 255=SNA; unit degC}, end-to-end-transformation-i-signal-props=data-ids=0  # Tire Temperature Front Left"
          signal ALIVE_TPMS_01: start 23, 8 bit, big-endian, init-value=0, base-type=uint8, compu {raw=phys for phys 0..255}, end-to-end-transformation-i-signal-props=data-ids=0  # Alive Counter"
          signal CRC_TPMS_01: start 7, 16 bit, big-endian, init-value=0, base-type=uint16, compu {raw=phys for phys 0..65535}, end-to-end-transformation-i-signal-props=data-ids=0  # DataID=0x005D. Checksum calculation accordig CAN Specification. Cyclic Redundancy Check"
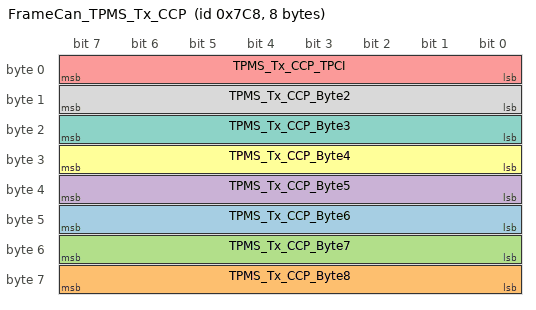
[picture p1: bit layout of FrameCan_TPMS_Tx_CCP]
      frame FrameCan_TPMS_Tx_CCP: id 0x7C8, from Ecu_TPMS, frame-length=8, can-addressing-mode=STANDARD, can-frame-tx-behavior=CAN-20
        carries pdu IPduISignal_TPMS_Tx_CCP: packing-byte-order=big-endian, start-position=7
        pdu IPduISignal_TPMS_Tx_CCP: length=8, transmission-mode-false-timing=event-controlled-timing=number-of-repetitions=0, transmission-mode-true-timing=event-controlled-timing=number-of-repetitions=0
          transmission-mode-conditions:
            {data-filter={data-filter-type=ALWAYS, max=255, min=0, offset=0}, i-signal-in-i-pdu=TPMS_Tx_CCP_Byte6}
            {data-filter={data-filter-type=ALWAYS, max=255, min=0, offset=0}, i-signal-in-i-pdu=TPMS_Tx_CCP_Byte8}
            {data-filter={data-filter-type=ALWAYS, max=255, min=0, offset=0}, i-signal-in-i-pdu=TPMS_Tx_CCP_Byte7}
            {data-filter={data-filter-type=ALWAYS, max=255, min=0, offset=0}, i-signal-in-i-pdu=TPMS_Tx_CCP_Byte5}
            {data-filter={data-filter-type=ALWAYS, max=255, min=0, offset=0}, i-signal-in-i-pdu=TPMS_Tx_CCP_TPCI}
            {data-filter={data-filter-type=ALWAYS, max=255, min=0, offset=0}, i-signal-in-i-pdu=TPMS_Tx_CCP_Byte4}
            {data-filter={data-filter-type=ALWAYS, max=255, min=0, offset=0}, i-signal-in-i-pdu=TPMS_Tx_CCP_Byte3}
            {data-filter={data-filter-type=ALWAYS, max=255, min=0, offset=0}, i-signal-in-i-pdu=TPMS_Tx_CCP_Byte2}
          signal TPMS_Tx_CCP_Byte6: start 47, 8 bit, big-endian, init-value=0, base-type=uint8, compu {raw=phys for phys 0..255}, end-to-end-transformation-i-signal-props=data-ids=0  # CCP signal"
          signal TPMS_Tx_CCP_Byte8: start 63, 8 bit, big-endian, init-value=0, base-type=uint8, compu {raw=phys for phys 0..255}, end-to-end-transformation-i-signal-props=data-ids=0  # CCP signal"
          signal TPMS_Tx_CCP_Byte7: start 55, 8 bit, big-endian, init-value=0, base-type=uint8, compu {raw=phys for phys 0..255}, end-to-end-transformation-i-signal-props=data-ids=0  # CCP signal"
          signal TPMS_Tx_CCP_Byte5: start 39, 8 bit, big-endian, init-value=0, base-type=uint8, compu {raw=phys for phys 0..255}, end-to-end-transformation-i-signal-props=data-ids=0  # CCP signal"
          signal TPMS_Tx_CCP_TPCI: start 7, 8 bit, big-endian, init-value=0, base-type=uint8, compu {raw=phys for phys 0..255}, end-to-end-transformation-i-signal-props=data-ids=0  # CCP signal"
          signal TPMS_Tx_CCP_Byte4: start 31, 8 bit, big-endian, init-value=0, base-type=uint8, compu {raw=phys for phys 0..255}, end-to-end-transformation-i-signal-props=data-ids=0  # CCP signal"
          signal TPMS_Tx_CCP_Byte3: start 23, 8 bit, big-endian, init-value=0, base-type=uint8, compu {raw=phys for phys 0..255}, end-to-end-transformation-i-signal-props=data-ids=0  # CCP signal"
          signal TPMS_Tx_CCP_Byte2: start 15, 8 bit, big-endian, init-value=0, base-type=uint8, compu {raw=phys for phys 0..255}, end-to-end-transformation-i-signal-props=data-ids=0  # CCP signal"
      frame FrameCan_WarnMsg_TPMS: id 0x419, from Ecu_TPMS, frame-length=6, can-addressing-mode=STANDARD, can-frame-tx-behavior=CAN-20  # Warning message to HU"
        carries pdu IPduISignal_WarnMsg_TPMS: packing-byte-order=big-endian, start-position=7
        pdu IPduISignal_WarnMsg_TPMS: length=6, transmission-mode-false-timing=cyclic-timing={time-offset=0.0, time-period=1.0}, transmission-mode-true-timing=cyclic-timing={time-offset=0.0, time-period=1.0}  # Warning message to HU
          transmission-mode-conditions:
            {data-filter={data-filter-type=NEW-IS-WITHIN, max=65535, min=0, offset=0}, i-signal-in-i-pdu=WarningMessageID_TPMS}
            {data-filter={data-filter-type=ALWAYS, max=3, min=0, offset=0}, i-signal-in-i-pdu=BitBlinking_TPMS}
            {data-filter={data-filter-type=ALWAYS, max=3, min=0, offset=0}, i-signal-in-i-pdu=BitStatus_TPMS}
            {data-filter={data-filter-type=NEW-IS-WITHIN, max=65535, min=0, offset=0}, i-signal-in-i-pdu=CRC_WarnMsg_TPMS}
            {data-filter={data-filter-type=ALWAYS, max=255, min=0, offset=0}, i-signal-in-i-pdu=ALIVE_WarnMsg_TPMS}
          signal WarningMessageID_TPMS: start 39, 16 bit, big-endian, init-value=0, base-type=uint16, compu {raw=phys for phys 0..65535}, end-to-end-transformation-i-signal-props=data-ids=0  # The value (0-65534) defines the warning message ID (details see warning message cataloge). "
          signal BitBlinking_TPMS: start 27, 2 bit, big-endian, init-value=0, base-type=uint8, compu {phys=raw for raw 0..3, 0=NOACTION, 1=ONEHZ, 2=THREEHZ, 3=SIGNALINVALID; unit Bit}, end-to-end-transformation-i-signal-props=data-ids=0  # This parameter defines the blinking frequency of a telltale"
          signal BitStatus_TPMS: start 25, 2 bit, big-endian, init-value=1, base-type=uint8, compu {phys=raw for raw 0..3, 0=SET, 1=RESET, 2=RESERVED, 3=SIGNALINVALID; unit Bit}, end-to-end-transformation-i-signal-props=data-ids=0  # The status defines if a warning message is set or reset"
          signal CRC_WarnMsg_TPMS: start 7, 16 bit, big-endian, init-value=0, base-type=uint16, compu {raw=phys for phys 0..65535}, end-to-end-transformation-i-signal-props=data-ids=0  # DataID=0x0089. Checksum calculation accordig CAN Specification. Cyclic Redundancy Check"
          signal ALIVE_WarnMsg_TPMS: start 23, 8 bit, big-endian, init-value=0, base-type=uint8, compu {raw=phys for phys 0..255}, end-to-end-transformation-i-signal-props=data-ids=0  # Alive Counter"
      pdu triggering TriggerPdu_Meas_TPMS_1_MUX_STAT: pdu=IPduISignal_Meas_TPMS_1_MUX_STAT, from Ecu_TPMS
      pdu triggering TriggerPdu_Meas_TPMS_1_MUX1: pdu=IPduISignal_Meas_TPMS_1_MUX1, from Ecu_TPMS
      pdu triggering TriggerPdu_Meas_TPMS_1_MUX2: pdu=IPduISignal_Meas_TPMS_1_MUX2, from Ecu_TPMS
package /DBC_SysDesc_Can_Network/Pkg_Pdus
  pdu IPduISignal_Meas_TPMS_1_MUX_STAT: length=8, transmission-mode-condition{data-filter={data-filter-type=ALWAYS, max=255, min=0, offset=0}, i-signal-in-i-pdu=Meas_TPM_1F}, transmission-mode-false-timing=event-controlled-timing=number-of-repetitions=0, transmission-mode-true-timing=event-controlled-timing=number-of-repetitions=0
    signal Meas_TPM_1F: start 47, 8 bit, big-endian, init-value=0, base-type=uint8, compu {raw=phys for phys 0..255}, end-to-end-transformation-i-signal-props=data-ids=0
  pdu IPduISignal_Meas_TPMS_1_MUX1: length=8, transmission-mode-false-timing=event-controlled-timing=number-of-repetitions=0, transmission-mode-true-timing=event-controlled-timing=number-of-repetitions=0
    transmission-mode-conditions:
      {data-filter={data-filter-type=ALWAYS, max=255, min=0, offset=0}, i-signal-in-i-pdu=Meas_TPM_1H}
      {data-filter={data-filter-type=ALWAYS, max=255, min=0, offset=0}, i-signal-in-i-pdu=Meas_TPM_1G}
      {data-filter={data-filter-type=ALWAYS, max=255, min=0, offset=0}, i-signal-in-i-pdu=Meas_TPM_1D}
      {data-filter={data-filter-type=ALWAYS, max=255, min=0, offset=0}, i-signal-in-i-pdu=Meas_TPM_1C}
      {data-filter={data-filter-type=ALWAYS, max=255, min=0, offset=0}, i-signal-in-i-pdu=Meas_TPM_1B}
      {data-filter={data-filter-type=ALWAYS, max=255, min=0, offset=0}, i-signal-in-i-pdu=Meas_TPM_1A}
    signal Meas_TPM_1H: start 63, 8 bit, big-endian, init-value=0, base-type=uint8, compu {raw=phys for phys 0..255}, end-to-end-transformation-i-signal-props=data-ids=0
    signal Meas_TPM_1G: start 55, 8 bit, big-endian, init-value=0, base-type=uint8, compu {raw=phys for phys 0..255}, end-to-end-transformation-i-signal-props=data-ids=0
    signal Meas_TPM_1D: start 31, 8 bit, big-endian, init-value=0, base-type=uint8, compu {raw=phys for phys 0..255}, end-to-end-transformation-i-signal-props=data-ids=0
    signal Meas_TPM_1C: start 23, 8 bit, big-endian, init-value=0, base-type=uint8, compu {raw=phys for phys 0..255}, end-to-end-transformation-i-signal-props=data-ids=0
    signal Meas_TPM_1B: start 15, 8 bit, big-endian, init-value=0, base-type=uint8, compu {raw=phys for phys 0..255}, end-to-end-transformation-i-signal-props=data-ids=0
    signal Meas_TPM_1A: start 39, 8 bit, big-endian, init-value=0, base-type=uint8, compu {raw=phys for phys 0..255}, end-to-end-transformation-i-signal-props=data-ids=0
    signal TPMS_MEAS_ID_1: start 7, 8 bit, big-endian, init-value=1, base-type=uint8, compu {raw=phys for phys 0}
  pdu IPduISignal_Meas_TPMS_1_MUX2: length=8, transmission-mode-condition{data-filter={data-filter-type=ALWAYS, max=255, min=0, offset=0}, i-signal-in-i-pdu=Meas_TPM_1E}, transmission-mode-false-timing=event-controlled-timing=number-of-repetitions=0, transmission-mode-true-timing=event-controlled-timing=number-of-repetitions=0
    signal Meas_TPM_1E: start 39, 8 bit, big-endian, init-value=0, base-type=uint8, compu {raw=phys for phys 0..255}, end-to-end-transformation-i-signal-props=data-ids=0
    signal TPMS_MEAS_ID_2: start 7, 8 bit, big-endian, init-value=2, base-type=uint8, compu {raw=phys for phys 0}
package /DBC_SysDesc_Can_Network/Pkg_Ecu
  ecu instance Ecu_TPMS: com-configuration-gw-time-base=0.005, com-configuration-rx-time-base=0.01, com-configuration-tx-time-base=0.01, sleep-mode-supported=false, wake-up-over-bus-supported=false
    can communication controller Controller_Network_Can_Node0_TPMS: can-controller-attributes=can-controller-configuration={prop-seg=0, sync-jump-width=0, time-seg-1=10, time-seg-2=0}
    can communication connector Connector_Network_Can_Node0_TPMS: comm-controller=Controller_Network_Can_Node0_TPMS
package /DBC_SysDesc_Can_Network/Pkg_Units
  16 x unit:
    kPa
    Tick
    d
    y
    pct
    degC
    mR
    min
    l_min
    rad_s
    cm
    h
    W
    Bit
    s
    km_h
package /System
  system System: category=SYSTEM_DESCRIPTION
    system mapping SystemMapping
      data-mappings:
        data-element=CPT_SwcApplTpmsCom.RootSwCompositionPrototype.RPort_SwcApplBcmCom_StatusKL.DataElement_eKL30R, system-signal=BCM_STAT_CL30R_L
        data-element=CPT_SwcApplBcmCom.RootSwCompositionPrototype.PPort_SwcApplBcmCom_StatusKL.DataElement_eKL30R, system-signal=BCM_STAT_CL30R_L
      sw-mappings:
        swc to ecu mapping SwcToEcuMapping_System: component=RootSwCompositionPrototype.CPT_SwcApplTpmsCom, ecu-instance=Ecu_TPMS
    root-software-compositions:
      root sw composition prototype RootSwCompositionPrototype: software-composition=TopLevelComposition
